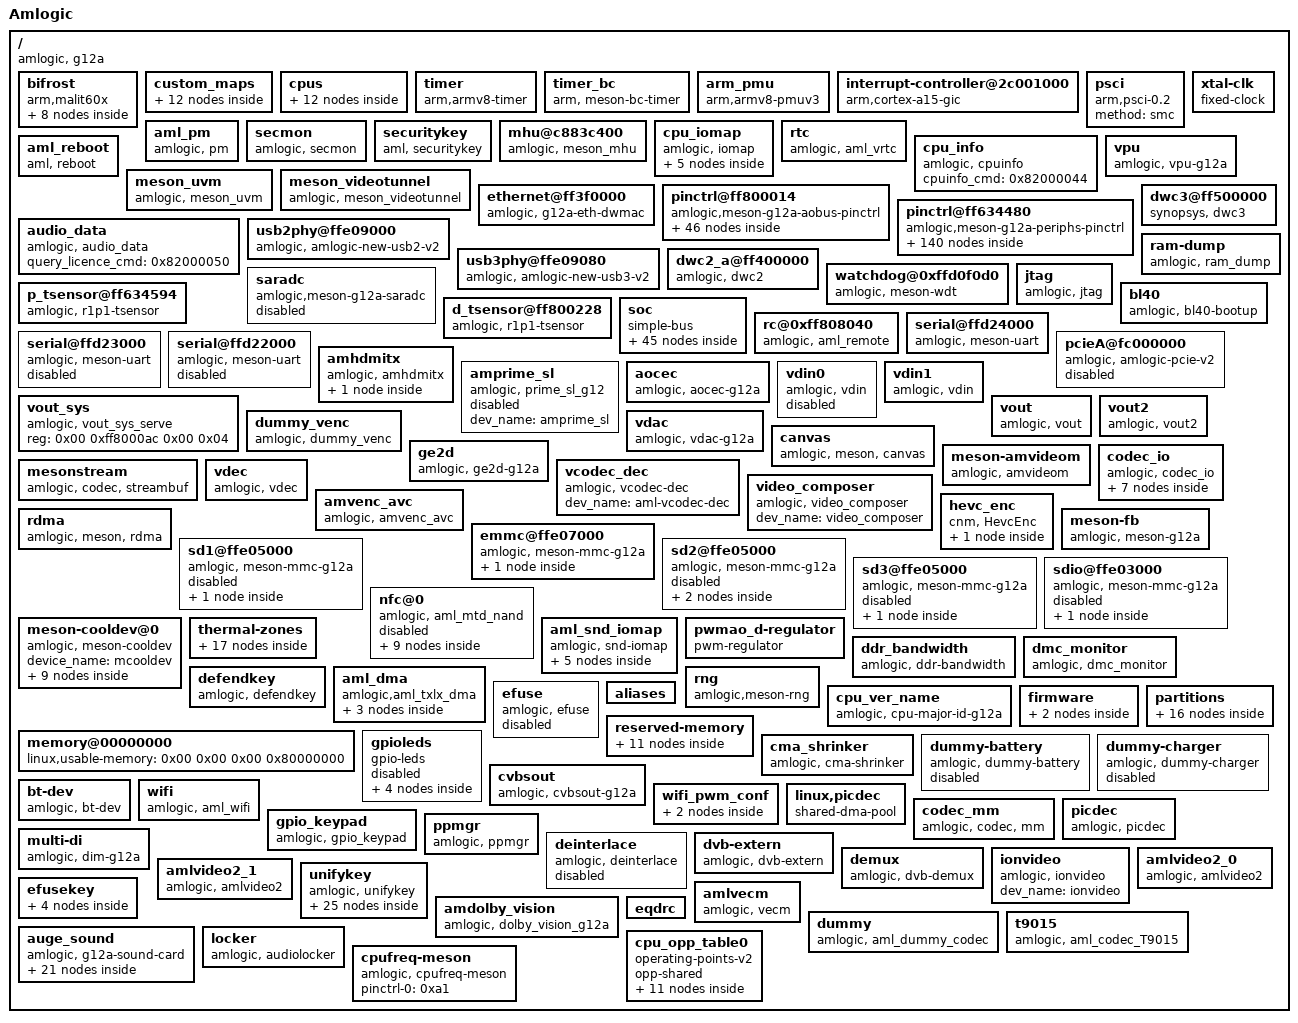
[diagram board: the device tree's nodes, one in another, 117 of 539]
/dts-v1/;

/ {
	model = "Amlogic";
	amlogic-dt-id = "g12a_u212_mtk";
	compatible = "amlogic, g12a";
	interrupt-parent = <0x01>;
	#address-cells = <0x02>;
	#size-cells = <0x02>;

	bifrost {
		compatible = "arm,malit60x", "arm,malit6xx", "arm,mali-midgard";
		#cooling-cells = <0x02>;
		reg = <0x00 0xffe40000 0x00 0x4000 0x00 0xffd01000 0x00 0x1000 0x00 0xff800000 0x00 0x1000 0x00 0xff63c000 0x00 0x1000 0x00 0xffd01000 0x00 0x1000>;
		interrupt-parent = <0x01>;
		interrupts = <0x00 0xa0 0x04 0x00 0xa1 0x04 0x00 0xa2 0x04>;
		interrupt-names = "GPU", "MMU", "JOB";
		num_of_pp = <0x02>;
		sc_mpp = <0x01>;
		clocks = <0x02 0x83 0x02 0x07>;
		clock-names = "gpu_mux", "gp0_pll";
		tbl = <0x03 0x04 0x05 0x06 0x07 0x07>;
		phandle = <0xa2>;

		clk125_cfg {
			clk_freq = <0x7735940>;
			clk_parent = "fclk_div4";
			clkp_freq = <0x1dcd6500>;
			clk_reg = <0xa03>;
			voltage = <0x47e>;
			keep_count = <0x05>;
			threshold = <0x1e 0x78>;
			phandle = <0xa3>;
		};

		dvfs250_cfg {
			clk_freq = <0xee6b280>;
			clk_parent = "fclk_div4";
			clkp_freq = <0x1dcd6500>;
			clk_reg = <0xa01>;
			voltage = <0x47e>;
			keep_count = <0x05>;
			threshold = <0x50 0xaa>;
			phandle = <0xa4>;
		};

		dvfs285_cfg {
			clk_freq = <0x1107a76d>;
			clk_parent = "fclk_div7";
			clkp_freq = <0x1107a76d>;
			clk_reg = <0xe00>;
			voltage = <0x47e>;
			keep_count = <0x05>;
			threshold = <0x00 0x4c>;
			phandle = <0x03>;
		};

		dvfs400_cfg {
			clk_freq = <0x17d78400>;
			clk_parent = "fclk_div5";
			clkp_freq = <0x17d78400>;
			clk_reg = <0xc00>;
			voltage = <0x47e>;
			keep_count = <0x05>;
			threshold = <0x98 0xcf>;
			phandle = <0x04>;
		};

		dvfs500_cfg {
			clk_freq = <0x1dcd6500>;
			clk_parent = "fclk_div4";
			clkp_freq = <0x1dcd6500>;
			clk_reg = <0xa00>;
			voltage = <0x47e>;
			keep_count = <0x05>;
			threshold = <0x26 0xc2>;
			phandle = <0x05>;
		};

		dvfs666_cfg {
			clk_freq = <0x27bc86aa>;
			clk_parent = "fclk_div3";
			clkp_freq = <0x27bc86aa>;
			clk_reg = <0x800>;
			voltage = <0x47e>;
			keep_count = <0x05>;
			threshold = <0x96 0xcb>;
			phandle = <0x06>;
		};

		dvfs800_cfg {
			clk_freq = <0x2faf0800>;
			clk_parent = "fclk_div2p5";
			clkp_freq = <0x2faf0800>;
			clk_reg = <0x600>;
			voltage = <0x47e>;
			keep_count = <0x05>;
			threshold = <0xe6 0xff>;
			phandle = <0xa5>;
		};

		dvfs850_cfg {
			clk_freq = <0x326cef80>;
			clk_parent = "gp0_pll";
			clkp_freq = <0x326cef80>;
			clk_reg = <0x200>;
			voltage = <0x47e>;
			keep_count = <0x05>;
			threshold = <0x9c 0xff>;
			phandle = <0x07>;
		};
	};

	custom_maps {
		mapnum = <0x0c>;
		map0 = <0x08>;
		map1 = <0x09>;
		map2 = <0x0a>;
		map3 = <0x0b>;
		map4 = <0x0c>;
		map5 = <0x0d>;
		map6 = <0x0e>;
		map7 = <0x0f>;
		map8 = <0x10>;
		map9 = <0x11>;
		map10 = <0x12>;
		map11 = <0x13>;
		phandle = <0x35>;

		map_0 {
			mapname = "amlogic-remote-1";
			customcode = <0xfb04>;
			release_delay = <0x50>;
			size = <0x00>;
			keymap;
			phandle = <0x08>;
		};

		map_1 {
			mapname = "amlogic-remote-2";
			customcode = <0xfe01>;
			release_delay = <0x50>;
			size = <0x00>;
			keymap;
			phandle = <0x09>;
		};

		map_2 {
			mapname = "amlogic-remote-3";
			customcode = <0x00>;
			release_delay = <0x50>;
			size = <0x00>;
			keymap;
			phandle = <0x0a>;
		};

		map_3 {
			mapname = "amlogic-remote-4";
			customcode = <0xff00>;
			release_delay = <0x50>;
			size = <0x28>;
			keymap = <0x0b 0x10002 0x20003 0x30004 0x40005 0x50006 0x60007 0x70008 0x80009 0x9000a 0x1e0166 0xa000f 0x450080 0x470067 0x4b006c 0x490061 0x480069 0x4a006a 0x150193 0xb0192 0xc0073 0x180072 0xd0068 0x13006d 0x460078 0x430079 0x5600ac 0x440077 0x400074 0x120071 0x4e0180 0x4f017a 0x50017d 0x51016e 0x4c009e 0x16000e 0x1c00ab 0x1d009c 0x110194 0x4d008b>;
			phandle = <0x0b>;
		};

		map_4 {
			mapname = "amlogic-remote-5";
			customcode = <0x4db2>;
			release_delay = <0x50>;
			size = <0x31>;
			keymap = <0xca0067 0xd2006c 0x990069 0xc1006a 0xce0061 0x800073 0x810072 0xc5009e 0x8200ac 0x9c0071 0xdc0074 0x88008b 0x950077 0x920002 0x930003 0xcc0004 0x8e0005 0x8f0006 0xc80007 0x8a0008 0x8b0009 0xc4000a 0x87000b 0xde0034 0xf3016a 0xc30166 0x8d009c 0xdf000e 0xfe00da 0xe90244 0x910195 0x310188 0x320090 0xcd0189 0x8301ba 0xe6003b 0xe7003c 0xe8003d 0xea00b1 0x4300a8 0x4600d0 0x3400a7 0xe30031 0xe40058 0x330057 0xec0181 0x850192 0x860193 0xeb00b2>;
			phandle = <0x0c>;
		};

		map_5 {
			mapname = "amlogic-remote-6";
			customcode = <0xb24d>;
			release_delay = <0x50>;
			size = <0x2e>;
			keymap = <0xca0067 0xd2006c 0x990069 0xc1006a 0xce001c 0x800073 0x810072 0x8d008d 0xc5009e 0x8200ac 0x9c0071 0xdc0074 0x88008b 0x950077 0x920002 0x930003 0xcc0004 0x8e0005 0x8f0006 0xc80007 0x8a0008 0x8b0009 0xc4000a 0x87000b 0xde0034 0xc30166 0xf3016a 0xdf000e 0xe90244 0x910195 0x310188 0x320090 0xcd0189 0x8301ba 0xe6003b 0xe7003c 0xe8003d 0xea003e 0x4300a8 0x4600d0 0x3400a7 0xe30245 0xe40058 0x330057 0x850192 0x860193>;
			phandle = <0x0d>;
		};

		map_6 {
			mapname = "amlogic-remote-7";
			customcode = <0x04>;
			release_delay = <0x5a>;
			size = <0x2a>;
			keymap = <0xc0074 0x61009c 0x3c0040 0x6b003c 0x6c003d 0x6d003e 0x6e003f 0x5100a5 0x3600a6 0x5000a3 0x3200a8 0x3500a4 0x3400d0 0x1200ac 0x3700a7 0x41016a 0x100067 0x150069 0x24001c 0x16006a 0x11006c 0x1f009e 0x4a0166 0x1d0041 0x140073 0x2700d9 0xe0192 0x170072 0xd0071 0xa0193 0x10002 0x20003 0x30004 0x40005 0x50006 0x60007 0x70008 0x80009 0x9000a 0x25000e 0x0b 0x260042>;
			phandle = <0x0e>;
		};

		map_7 {
			mapname = "amlogic-remote-8";
			customcode = <0xbf00>;
			release_delay = <0x50>;
			size = <0x18>;
			keymap = <0x150067 0x16006c 0x170069 0x18006a 0x140061 0x520073 0x530072 0x51009e 0x700ac 0x460071 0x430074 0xb0002 0xc0003 0xd0004 0xe0005 0xf0006 0x10007 0x110008 0x120009 0x13000a 0xa000b 0x4b0192 0x4c0193 0x600da>;
			phandle = <0x0f>;
		};

		map_8 {
			mapname = "amlogic-remote-9";
			customcode = <0x5e87>;
			release_delay = <0x50>;
			size = <0x2b>;
			keymap = <0x3400a8 0x3600a4 0x35009f 0x38018b 0x320080 0x3300a7 0x390066 0x200188 0x2800db 0x23008b 0x48016a 0xa00ae 0x130166 0xf008a 0xb0067 0x1b0069 0x1c006a 0xc006c 0x15001c 0xd0073 0xe0072 0x1d016c 0x2901a9 0x100192 0x1a0193 0x11019c 0x10002 0x20003 0x30004 0x40005 0x50006 0x60007 0x70008 0x80009 0x9000a 0x0b 0x540172 0x210177 0x180190 0x190191 0x16018e 0x17018f 0x120074>;
			phandle = <0x10>;
		};

		map_9 {
			mapname = "amlogic-remote-10";
			customcode = <0xfd01>;
			release_delay = <0x50>;
			size = <0x27>;
			keymap = <0x8c00a8 0xdd009f 0x98018b 0x91009b 0xc60190 0x9d0188 0x88018f 0x95008b 0xda0191 0xc500ae 0xd6008a 0x830166 0xca0067 0x990069 0xc1006a 0xd2006c 0xce001c 0x850073 0x860072 0x8d016c 0xc7018e 0x800192 0x810193 0x82019c 0x9c0071 0x920002 0x930003 0xcc0004 0x8e0005 0x8f0006 0xc80007 0x8a0008 0x8b0009 0xc4000a 0x87000b 0x840172 0xc90172 0xcd0177 0xdc0074>;
			phandle = <0x11>;
		};

		map_10 {
			mapname = "amlogic-remote-11";
			customcode = <0xbd02>;
			release_delay = <0x50>;
			size = <0x34>;
			keymap = <0x4600a8 0x9500a4 0x47009f 0x48018b 0x490080 0x5000a7 0x51009b 0xa000d9 0x5b0177 0xab0043 0x520066 0x530188 0x5400db 0xd6008d 0x55016a 0xd000ae 0x56008a 0x570166 0xca0067 0x990069 0xc1006a 0xd2006c 0xce001c 0xdd0073 0x8c0072 0x58016c 0x5901a9 0x600192 0x610193 0x62019c 0x890071 0x640002 0x650003 0x660004 0x670005 0x680006 0x690007 0x700008 0x710009 0x72000a 0x63000b 0xa1003b 0xa2003c 0xa3003d 0xa4003e 0x730172 0x740177 0x9a0190 0xcd0191 0x9c018e 0x9d018f 0x450074>;
			phandle = <0x12>;
		};

		map_11 {
			mapname = "amlogic-remote-12";
			customcode = <0xf708>;
			release_delay = <0x50>;
			size = <0x2a>;
			keymap = <0xa0074 0x5018e 0x9018f 0x420190 0x430191 0x4400a8 0x4500d0 0x620041 0x5b003c 0x400166 0x700a4 0xb0080 0x6003d 0x8003e 0x1c009e 0xc00ac 0x660244 0x7e0044 0x67 0x1006c 0x30069 0x2006a 0x1f0061 0x580073 0x5d0072 0x5a0192 0x5f0193 0x7400da 0xd0071 0x110002 0x120003 0x130004 0x140005 0x150006 0x160007 0x170008 0x180009 0x19000a 0x10000b 0x7700d7 0x61009c 0x30000e>;
			phandle = <0x13>;
		};
	};

	cpus {
		#address-cells = <0x02>;
		#size-cells = <0x00>;
		phandle = <0xa6>;

		cpu-map {

			cluster0 {
				phandle = <0xa7>;

				core0 {
					cpu = <0x14>;
				};

				core1 {
					cpu = <0x15>;
				};

				core2 {
					cpu = <0x16>;
				};

				core3 {
					cpu = <0x17>;
				};
			};
		};

		cpu@0 {
			device_type = "cpu";
			compatible = "arm,cortex-a53", "arm,armv8";
			reg = <0x00 0x00>;
			enable-method = "psci";
			cpu-idle-states = <0x18>;
			clocks = <0x02 0x17 0x02 0x16 0x02 0x00>;
			clock-names = "core_clk", "low_freq_clk_parent", "high_freq_clk_parent";
			operating-points-v2 = <0x19>;
			cpu-supply = <0x1a>;
			voltage-tolerance = <0x00>;
			clock-latency = <0xc350>;
			phandle = <0x14>;
		};

		cpu@1 {
			device_type = "cpu";
			compatible = "arm,cortex-a53", "arm,armv8";
			reg = <0x00 0x01>;
			enable-method = "psci";
			cpu-idle-states = <0x18>;
			clocks = <0x02 0x17 0x02 0x16 0x02 0x00>;
			clock-names = "core_clk", "low_freq_clk_parent", "high_freq_clk_parent";
			operating-points-v2 = <0x19>;
			cpu-supply = <0x1a>;
			voltage-tolerance = <0x00>;
			clock-latency = <0xc350>;
			phandle = <0x15>;
		};

		cpu@2 {
			device_type = "cpu";
			compatible = "arm,cortex-a53", "arm,armv8";
			reg = <0x00 0x02>;
			enable-method = "psci";
			cpu-idle-states = <0x18>;
			clocks = <0x02 0x17 0x02 0x16 0x02 0x00>;
			clock-names = "core_clk", "low_freq_clk_parent", "high_freq_clk_parent";
			operating-points-v2 = <0x19>;
			cpu-supply = <0x1a>;
			voltage-tolerance = <0x00>;
			clock-latency = <0xc350>;
			phandle = <0x16>;
		};

		cpu@3 {
			device_type = "cpu";
			compatible = "arm,cortex-a53", "arm,armv8";
			reg = <0x00 0x03>;
			enable-method = "psci";
			cpu-idle-states = <0x18>;
			clocks = <0x02 0x17 0x02 0x16 0x02 0x00>;
			clock-names = "core_clk", "low_freq_clk_parent", "high_freq_clk_parent";
			operating-points-v2 = <0x19>;
			cpu-supply = <0x1a>;
			voltage-tolerance = <0x00>;
			clock-latency = <0xc350>;
			phandle = <0x17>;
		};

		idle-states {
			entry-method = "arm,psci-0.2";

			cpu-sleep-0 {
				compatible = "arm,idle-state";
				arm,psci-suspend-param = <0x10000>;
				local-timer-stop;
				entry-latency-us = <0x1388>;
				exit-latency-us = <0x1388>;
				min-residency-us = <0x3a98>;
				phandle = <0x18>;
			};
		};
	};

	timer {
		compatible = "arm,armv8-timer";
		interrupts = <0x01 0x0d 0xff08 0x01 0x0e 0xff08 0x01 0x0b 0xff08 0x01 0x0a 0xff08>;
	};

	timer_bc {
		compatible = "arm, meson-bc-timer";
		reg = <0x00 0xffd0f190 0x00 0x04 0x00 0xffd0f194 0x00 0x04>;
		timer_name = "Meson TimerF";
		clockevent-rating = <0x12c>;
		clockevent-shift = <0x14>;
		clockevent-features = <0x23>;
		interrupts = <0x00 0x3c 0x01>;
		bit_enable = <0x10>;
		bit_mode = <0x0c>;
		bit_resolution = <0x00>;
	};

	arm_pmu {
		compatible = "arm,armv8-pmuv3";
		interrupts = <0x00 0x89 0x04>;
		reg = <0x00 0xff634680 0x00 0x04>;
		cpumasks = <0x0f>;
		relax-timer-ns = <0x989680>;
		max-wait-cnt = <0x2710>;
	};

	interrupt-controller@2c001000 {
		compatible = "arm,cortex-a15-gic", "arm,cortex-a9-gic";
		#interrupt-cells = <0x03>;
		#address-cells = <0x00>;
		interrupt-controller;
		reg = <0x00 0xffc01000 0x00 0x1000 0x00 0xffc02000 0x00 0x100>;
		interrupts = <0x01 0x09 0xf04>;
		phandle = <0x01>;
	};

	psci {
		compatible = "arm,psci-0.2";
		method = "smc";
	};

	aml_pm {
		compatible = "amlogic, pm";
		status = "okay";
		device_name = "aml_pm";
		debug_reg = <0xff8000a8>;
		exit_reg = <0xff80023c>;
	};

	secmon {
		compatible = "amlogic, secmon";
		memory-region = <0x1b>;
		in_base_func = <0x82000020>;
		out_base_func = <0x82000021>;
		reserve_mem_size = <0x300000>;
	};

	securitykey {
		compatible = "aml, securitykey";
		storage_query = <0x82000060>;
		storage_read = <0x82000061>;
		storage_write = <0x82000062>;
		storage_tell = <0x82000063>;
		storage_verify = <0x82000064>;
		storage_status = <0x82000065>;
		storage_list = <0x82000067>;
		storage_remove = <0x82000068>;
		storage_in_func = <0x82000023>;
		storage_out_func = <0x82000024>;
		storage_block_func = <0x82000025>;
		storage_size_func = <0x82000027>;
		storage_set_enctype = <0x8200006a>;
		storage_get_enctype = <0x8200006b>;
		storage_version = <0x8200006c>;
	};

	mhu@c883c400 {
		compatible = "amlogic, meson_mhu";
		reg = <0x00 0xff63c400 0x00 0x4c 0x00 0xfffe7000 0x00 0x800>;
		interrupts = <0x00 0xd1 0x01 0x00 0xd2 0x01 0x00 0xd5 0x01>;
		#mbox-cells = <0x01>;
		mbox-names = "cpu_to_scp_low", "bl4_to_cpu", "cpu_to_bl4";
		mboxes = <0x1c 0x00 0x1c 0x01 0x1c 0x02>;
		num-chans-to-scp = <0x01>;
		send-isr-bits = <0x05>;
		ack-isr-bits = <0x04>;
		m4-isr-bits = <0x06>;
		mbox-chans = <0x03>;
		phandle = <0x1c>;
	};

	cpu_iomap {
		compatible = "amlogic, iomap";
		#address-cells = <0x02>;
		#size-cells = <0x02>;
		ranges;

		io_cbus_base {
			reg = <0x00 0xffd00000 0x00 0x26000>;
		};

		io_apb_base {
			reg = <0x00 0xffe01000 0x00 0x7f000>;
		};

		io_aobus_base {
			reg = <0x00 0xff800000 0x00 0xb000>;
		};

		io_vapb_base {
			reg = <0x00 0xff900000 0x00 0x50000>;
		};

		io_hiu_base {
			reg = <0x00 0xff63c000 0x00 0x2000>;
		};
	};

	xtal-clk {
		compatible = "fixed-clock";
		clock-frequency = <0x16e3600>;
		clock-output-names = "xtal";
		#clock-cells = <0x00>;
		phandle = <0x1f>;
	};

	rtc {
		compatible = "amlogic, aml_vrtc";
		alarm_reg_addr = <0xff8000a8>;
		timer_e_addr = <0xffd0f188>;
		init_date = "2015/01/01";
		status = "okay";
	};

	cpu_info {
		compatible = "amlogic, cpuinfo";
		status = "okay";
		cpuinfo_cmd = <0x82000044>;
	};

	aml_reboot {
		compatible = "aml, reboot";
		sys_reset = <0x84000009>;
		sys_poweroff = <0x84000008>;
	};

	vpu {
		compatible = "amlogic, vpu-g12a";
		dev_name = "vpu";
		status = "okay";
		clocks = <0x02 0x95 0x02 0x4c 0x02 0x87 0x02 0x8b 0x02 0x8c>;
		clock-names = "vapb_clk", "vpu_intr_gate", "vpu_clk0", "vpu_clk1", "vpu_clk";
		clk_level = <0x07>;
	};

	meson_uvm {
		compatible = "amlogic, meson_uvm";
		status = "okay";
	};

	meson_videotunnel {
		compatible = "amlogic, meson_videotunnel";
		status = "okay";
	};

	ethernet@ff3f0000 {
		compatible = "amlogic, g12a-eth-dwmac", "snps,dwmac";
		reg = <0x00 0xff3f0000 0x00 0x10000 0x00 0xff634540 0x00 0x08 0x00 0xff64c000 0x00 0xa0 0x00 0xffd01008 0x00 0x04>;
		reg-names = "eth_base", "eth_cfg", "eth_pll", "eth_reset";
		interrupts = <0x00 0x08 0x01>;
		interrupt-names = "macirq";
		status = "okay";
		clocks = <0x02 0x38>;
		clock-names = "ethclk81";
		pll_val = <0x9c0040a 0x927e0000 0xac5f49e5>;
		analog_val = <0x20200000 0xc000 0x23>;
		pinctrl-names = "internal_eth_pins", "internal_gpio_pins";
		mc_val = <0x4be04>;
		internal_phy = <0x01>;
		phandle = <0xa8>;
	};

	pinctrl@ff800014 {
		compatible = "amlogic,meson-g12a-aobus-pinctrl";
		#address-cells = <0x02>;
		#size-cells = <0x02>;
		ranges;
		phandle = <0xa9>;

		ao-bank@ff800014 {
			reg = <0x00 0xff800014 0x00 0x08 0x00 0xff800024 0x00 0x14 0x00 0xff80001c 0x00 0x08>;
			reg-names = "mux", "gpio", "drive-strength";
			gpio-controller;
			#gpio-cells = <0x02>;
			phandle = <0x71>;
		};

		sd_to_ao_uart_clr_pins {
			phandle = <0x48>;

			mux {
				groups = "GPIOAO_0", "GPIOAO_1";
				function = "gpio_aobus";
			};
		};

		sd_to_ao_uart_pins {
			phandle = <0x4a>;

			mux {
				groups = "uart_ao_tx_a", "uart_ao_rx_a";
				function = "uart_ao_a";
				bias-pull-up;
				input-enable;
			};
		};

		ao_uart {
			phandle = <0xaa>;

			mux {
				groups = "uart_ao_tx_a", "uart_ao_rx_a";
				function = "uart_ao_a";
			};
		};

		ao_b_uart {
			phandle = <0x27>;

			mux {
				groups = "uart_ao_tx_b_2", "uart_ao_rx_b_3";
				function = "uart_ao_b";
			};
		};

		ao_i2c_pins1 {
			phandle = <0xab>;

			mux {
				groups = "i2c_ao_sck", "i2c_ao_sda";
				function = "i2c_ao";
				drive-strength = <0x02>;
			};
		};

		ao_i2c_pins2 {
			phandle = <0xac>;

			mux {
				groups = "i2c_ao_sck_e", "i2c_ao_sda_e";
				function = "i2c_ao";
				drive-strength = <0x02>;
			};
		};

		ao_i2c_slave_pins {
			phandle = <0x26>;

			mux {
				groups = "i2c_ao_slave_sck", "i2c_ao_slave_sda";
				function = "i2c_ao_slave";
			};
		};

		pwm_ao_a {
			phandle = <0xad>;

			mux {
				groups = "pwm_ao_a";
				function = "pwm_ao_a";
			};
		};

		pwm_ao_a_hiz {
			phandle = <0xae>;

			mux {
				groups = "pwm_ao_a_hiz";
				function = "pwm_ao_a";
			};
		};

		pwm_ao_b {
			phandle = <0xaf>;

			mux {
				groups = "pwm_ao_b";
				function = "pwm_ao_b";
			};
		};

		pwm_ao_c_pins1 {
			phandle = <0xb0>;

			mux {
				groups = "pwm_ao_c_4";
				function = "pwm_ao_c";
			};
		};

		pwm_ao_c_pins2 {
			phandle = <0xb1>;

			mux {
				groups = "pwm_ao_c_6";
				function = "pwm_ao_c";
			};
		};

		pwm_ao_c_hiz {
			phandle = <0xb2>;

			mux {
				groups = "pwm_ao_c_hiz_4";
				function = "pwm_ao_c";
			};
		};

		pwm_ao_d_pins1 {
			phandle = <0xb3>;

			mux {
				groups = "pwm_ao_d_5";
				function = "pwm_ao_d";
			};
		};

		pwm_ao_d_pins2 {
			phandle = <0xb4>;

			mux {
				groups = "pwm_ao_d_10";
				function = "pwm_ao_d";
			};
		};

		pwm_ao_d_pins3 {
			phandle = <0xa1>;

			mux {
				groups = "pwm_ao_d_e";
				function = "pwm_ao_d";
			};
		};

		ao_ceca {
			phandle = <0xb5>;

			mux {
				groups = "cec_ao_a";
				function = "cec_ao";
			};
		};

		ao_cecb {
			phandle = <0xb6>;

			mux {
				groups = "cec_ao_b";
				function = "cec_ao";
			};
		};

		jtag_apao_pin {
			phandle = <0x20>;

			mux {
				groups = "jtag_a_tdi", "jtag_a_tdo", "jtag_a_clk", "jtag_a_tms";
				function = "jtag_a";
			};
		};

		remote_pin {
			phandle = <0x34>;

			mux {
				groups = "remote_input_ao";
				function = "remote_input_ao";
			};
		};

		irblaster_pin {
			phandle = <0x28>;

			mux {
				groups = "remote_out_ao";
				function = "remote_out_ao";
			};
		};

		dvb_s_ts0_pins {
			phandle = <0xb7>;

			tsin_a_ao {
				groups = "tsin_a_sop_ao", "tsin_a_valid_ao", "tsin_a_clk_ao", "tsin_a_din0_ao";
				function = "tsin_a_ao";
			};

			tsin_a {
				groups = "tsin_a_sop_ao", "tsin_a_valid_ao", "tsin_a_clk_ao", "tsin_a_din0_ao";
				function = "tsin_a_ao";
			};
		};
	};

	pinctrl@ff634480 {
		compatible = "amlogic,meson-g12a-periphs-pinctrl";
		#address-cells = <0x02>;
		#size-cells = <0x02>;
		ranges;
		phandle = <0xb8>;

		banks@ff6346c0 {
			reg = <0x00 0xff6346c0 0x00 0x40 0x00 0xff6344e8 0x00 0x18 0x00 0xff634520 0x00 0x18 0x00 0xff634440 0x00 0x4c 0x00 0xff634740 0x00 0x1c>;
			reg-names = "mux", "pull", "pull-enable", "gpio", "drive-strength";
			gpio-controller;
			#gpio-cells = <0x02>;
			phandle = <0x23>;
		};

		emmc_clk_cmd_pins {
			phandle = <0x42>;

			mux {
				groups = "emmc_clk", "emmc_cmd";
				function = "emmc";
				input-enable;
				bias-pull-up;
			};
		};

		emmc_conf_pull_up {
			phandle = <0x43>;

			mux {
				groups = "emmc_nand_d7", "emmc_nand_d6", "emmc_nand_d5", "emmc_nand_d4", "emmc_nand_d3", "emmc_nand_d2", "emmc_nand_d1", "emmc_nand_d0", "emmc_clk", "emmc_cmd";
				function = "emmc";
				input-enable;
				bias-pull-up;
			};
		};

		emmc_conf_pull_done {
			phandle = <0x44>;

			mux {
				groups = "emmc_nand_ds";
				function = "emmc";
				input-enable;
				bias-pull-down;
			};
		};

		sd_clk_cmd_pins {
			phandle = <0x46>;

			mux {
				groups = "sdcard_cmd_c";
				function = "sdcard";
				input-enable;
				bias-pull-up;
				drive-strength = <0x03>;
			};

			mux1 {
				groups = "sdcard_clk_c";
				function = "sdcard";
				bias-pull-up;
				output-high;
				drive-strength = <0x03>;
			};
		};

		sd_all_pins {
			phandle = <0x45>;

			mux {
				groups = "sdcard_d0_c", "sdcard_d1_c", "sdcard_d2_c", "sdcard_d3_c", "sdcard_cmd_c";
				function = "sdcard";
				input-enable;
				bias-pull-up;
				drive-strength = <0x03>;
			};

			mux1 {
				groups = "sdcard_clk_c";
				function = "sdcard";
				bias-pull-up;
				output-high;
				drive-strength = <0x03>;
			};
		};

		sd_1bit_pins {
			phandle = <0x47>;

			mux {
				groups = "sdcard_d0_c", "sdcard_cmd_c";
				function = "sdcard";
				input-enable;
				bias-pull-up;
				drive-strength = <0x03>;
			};

			mux1 {
				groups = "sdcard_clk_c";
				function = "sdcard";
				bias-pull-up;
				output-high;
				drive-strength = <0x03>;
			};
		};

		sd_clr_all_pins {
			phandle = <0x4e>;

			mux {
				groups = "GPIOC_0", "GPIOC_1", "GPIOC_2", "GPIOC_3", "GPIOC_5";
				function = "gpio_periphs";
				output-high;
			};

			mux1 {
				groups = "GPIOC_4";
				function = "gpio_periphs";
				output-low;
			};
		};

		sd_clr_noall_pins {
			phandle = <0x4d>;

			mux {
				groups = "GPIOC_0", "GPIOC_1", "GPIOC_4", "GPIOC_5";
				function = "gpio_periphs";
				output-high;
			};
		};

		ao_to_sd_uart_pins {
			phandle = <0x49>;

			mux {
				groups = "uart_ao_tx_a_c3", "uart_ao_rx_a_c2";
				function = "uart_ao_a_ee";
				bias-pull-up;
				input-enable;
			};
		};

		sdio_clk_cmd_pins {
			phandle = <0x52>;

			mux {
				groups = "sdio_clk", "sdio_cmd";
				function = "sdio";
				input-enable;
				bias-pull-up;
				drive-strength = <0x03>;
			};
		};

		sdio_all_pins {
			phandle = <0x51>;

			mux {
				groups = "sdio_d0", "sdio_d1", "sdio_d2", "sdio_d3", "sdio_clk", "sdio_cmd";
				function = "sdio";
				input-enable;
				bias-pull-up;
				drive-strength = <0x03>;
			};
		};

		sdio_x_clk_cmd_pins {
			phandle = <0x50>;

			mux {
				groups = "GPIOX_5";
				function = "gpio_periphs";
				input-enable;
				bias-pull-up;
				drive-strength = <0x03>;
			};

			mux1 {
				groups = "GPIOX_4";
				function = "gpio_periphs";
				bias-pull-up;
				output-high;
				drive-strength = <0x03>;
			};
		};

		sdio_x_all_pins {
			phandle = <0x4f>;

			mux {
				groups = "GPIOX_0", "GPIOX_1", "GPIOX_2", "GPIOX_3", "GPIOX_5";
				function = "gpio_periphs";
				input-enable;
				bias-pull-up;
				drive-strength = <0x03>;
			};

			mux1 {
				groups = "GPIOX_4";
				function = "gpio_periphs";
				bias-pull-up;
				output-high;
				drive-strength = <0x03>;
			};
		};

		sdio_x_en_pins {
			phandle = <0x4c>;

			mux {
				groups = "sdio_dummy";
				function = "sdio";
				bias-pull-up;
				output-high;
			};
		};

		sdio_x_clr_pins {
			phandle = <0x4b>;

			mux {
				groups = "GPIOV_0";
				function = "gpio_periphs";
				bias-pull-up;
				output-low;
			};

			mux1 {
				groups = "GPIOX_4";
				function = "gpio_periphs";
				output-low;
			};
		};

		all_nand_pins {
			phandle = <0x53>;

			mux {
				groups = "emmc_nand_d0", "emmc_nand_d1", "emmc_nand_d2", "emmc_nand_d3", "emmc_nand_d4", "emmc_nand_d5", "emmc_nand_d6", "emmc_nand_d7", "nand_ce0", "nand_ale", "nand_cle", "nand_wen_clk", "nand_ren_wr", "nand_rb0";
				function = "nand";
				input-enable;
			};
		};

		nand_cs {
			phandle = <0x54>;

			mux {
				groups = "nand_ce0";
				function = "nand";
			};
		};

		i2c0_pins1 {
			phandle = <0xb9>;

			mux {
				groups = "i2c0_sda_c", "i2c0_sck_c";
				function = "i2c0";
				drive-strength = <0x02>;
			};
		};

		i2c0_pins2 {
			phandle = <0x22>;

			mux {
				groups = "i2c0_sda_z0", "i2c0_sck_z1";
				function = "i2c0";
				drive-strength = <0x02>;
			};
		};

		i2c0_pins3 {
			phandle = <0xba>;

			mux {
				groups = "i2c0_sda_z7", "i2c0_sck_z8";
				function = "i2c0";
				drive-strength = <0x02>;
			};
		};

		i2c1_pins1 {
			phandle = <0xbb>;

			mux {
				groups = "i2c1_sda_x", "i2c1_sck_x";
				function = "i2c1";
				drive-strength = <0x02>;
			};
		};

		i2c1_pins2 {
			phandle = <0xbc>;

			mux {
				groups = "i2c1_sda_h2", "i2c1_sck_h3";
				function = "i2c1";
				drive-strength = <0x02>;
			};
		};

		i2c1_pins3 {
			phandle = <0xbd>;

			mux {
				groups = "i2c1_sda_h6", "i2c1_sck_h7";
				function = "i2c1";
				drive-strength = <0x02>;
			};
		};

		i2c2_pins1 {
			phandle = <0xbe>;

			mux {
				groups = "i2c2_sda_x", "i2c2_sck_x";
				function = "i2c2";
				drive-strength = <0x02>;
			};
		};

		i2c2_pins2 {
			phandle = <0x24>;

			mux {
				groups = "i2c2_sda_z", "i2c2_sck_z";
				function = "i2c2";
				drive-strength = <0x02>;
			};
		};

		i2c3_pins1 {
			phandle = <0x3d>;

			mux {
				groups = "i2c3_sda_h", "i2c3_sck_h";
				function = "i2c3";
				drive-strength = <0x02>;
			};
		};

		i2c3_pins2 {
			phandle = <0x25>;

			mux {
				groups = "i2c3_sda_a", "i2c3_sck_a";
				function = "i2c3";
				drive-strength = <0x02>;
			};
		};

		pwm_a {
			phandle = <0xbf>;

			mux {
				groups = "pwm_a";
				function = "pwm_a";
			};
		};

		pwm_b_pins1 {
			phandle = <0xc0>;

			mux {
				groups = "pwm_b_x7";
				function = "pwm_b";
			};
		};

		pwm_b_pins2 {
			phandle = <0xc1>;

			mux {
				groups = "pwm_b_x19";
				function = "pwm_b";
			};
		};

		pwm_c_pins1 {
			phandle = <0xc2>;

			mux {
				groups = "pwm_c_c4";
				function = "pwm_c";
			};
		};

		pwm_c_pins2 {
			phandle = <0xc3>;

			mux {
				groups = "pwm_c_x5";
				function = "pwm_c";
			};
		};

		pwm_c_pins3 {
			phandle = <0xc4>;

			mux {
				groups = "pwm_c_x8";
				function = "pwm_c";
			};
		};

		pwm_d_pins1 {
			phandle = <0xc5>;

			mux {
				groups = "pwm_d_x3";
				function = "pwm_d";
			};
		};

		pwm_d_pins2 {
			phandle = <0xc6>;

			mux {
				groups = "pwm_d_x6";
				function = "pwm_d";
			};
		};

		pwm_e {
			phandle = <0xc7>;

			mux {
				groups = "pwm_e";
				function = "pwm_e";
				drive-strength = <0x00>;
			};
		};

		pwm_f_pins1 {
			phandle = <0xc8>;

			mux {
				groups = "pwm_f_x";
				function = "pwm_f";
			};
		};

		pwm_f_pins2 {
			phandle = <0xc9>;

			mux {
				groups = "pwm_f_h";
				function = "pwm_f";
			};
		};

		spicc0_pins_x {
			phandle = <0xca>;

			mux {
				groups = "spi0_mosi_x", "spi0_miso_x", "spi0_clk_x";
				function = "spi0";
				drive-strength = <0x01>;
			};
		};

		spicc0_pins_c {
			phandle = <0xcb>;

			mux {
				groups = "spi0_mosi_c", "spi0_miso_c", "spi0_ss0_c", "spi0_clk_c";
				function = "spi0";
				drive-strength = <0x01>;
			};
		};

		spicc1_pins {
			phandle = <0xcc>;

			mux {
				groups = "spi1_mosi", "spi1_miso", "spi1_clk";
				function = "spi1";
				drive-strength = <0x01>;
			};
		};

		a_uart {
			phandle = <0x36>;

			mux {
				groups = "uart_tx_a", "uart_rx_a", "uart_cts_a", "uart_rts_a";
				function = "uart_a";
			};
		};

		b_uart {
			phandle = <0x37>;

			mux {
				groups = "uart_tx_b", "uart_rx_b";
				function = "uart_b";
			};
		};

		c_uart {
			phandle = <0x38>;

			mux {
				groups = "uart_tx_c", "uart_rx_c";
				function = "uart_c";
			};
		};

		hdmitx_hpd {
			phandle = <0x3a>;

			mux {
				groups = "hdmitx_hpd_in";
				function = "hdmitx";
				bias-disable;
			};
		};

		hdmitx_hpd_gpio {
			phandle = <0x3c>;

			mux {
				groups = "GPIOH_1";
				function = "gpio_periphs";
				bias-disable;
			};
		};

		hdmitx_ddc {
			phandle = <0x3b>;

			mux {
				groups = "hdmitx_sda", "hdmitx_sck";
				function = "hdmitx";
				bias-disable;
				drive-strength = <0x03>;
			};
		};

		ee_ceca {
			phandle = <0x3e>;

			mux {
				groups = "cec_ao_a_ee";
				function = "cec_ao_ee";
			};
		};

		ee_cecb {
			phandle = <0x3f>;

			mux {
				groups = "cec_ao_b_ee";
				function = "cec_ao_ee";
			};
		};

		internal_eth_pins {
			phandle = <0xcd>;

			mux {
				groups = "eth_link_led", "eth_act_led";
				function = "eth";
			};
		};

		internal_gpio_pins {
			phandle = <0xce>;

			mux {
				groups = "GPIOZ_14", "GPIOZ_15";
				function = "gpio_periphs";
				bias-disable;
				input-enable;
			};
		};

		external_eth_pins {
			phandle = <0xcf>;

			mux {
				groups = "eth_mdio", "eth_mdc", "eth_rgmii_rx_clk", "eth_rx_dv", "eth_rxd0", "eth_rxd1", "eth_rxd2_rgmii", "eth_rxd3_rgmii", "eth_rgmii_tx_clk", "eth_txen", "eth_txd0", "eth_txd1", "eth_txd2_rgmii", "eth_txd3_rgmii";
				function = "eth";
				drive-strength = <0x03>;
			};
		};

		jtag_apee_pin {
			phandle = <0x21>;

			mux {
				groups = "jtag_b_tdi", "jtag_b_tdo", "jtag_b_clk", "jtag_b_tms";
				function = "jtag_b";
			};
		};

		tdmout_a {
			phandle = <0x2c>;

			mux {
				groups = "tdma_sclk", "tdma_fs", "tdma_dout0";
				function = "tdma_out";
			};
		};

		tdmin_a {
			phandle = <0x2d>;

			mux {
				groups = "tdma_din1";
				function = "tdma_in";
			};
		};

		tdmb_mclk {
			phandle = <0x2e>;

			mux {
				groups = "mclk0_a";
				function = "mclk0";
				drive-strength = <0x02>;
			};
		};

		tdmout_b {
			phandle = <0x2f>;

			mux {
				groups = "tdmb_sclk", "tdmb_fs", "tdmb_dout0";
				function = "tdmb_out";
				drive-strength = <0x02>;
			};
		};

		tdmin_b {
			phandle = <0x30>;

			mux {
				groups = "tdmb_din1";
				function = "tdmb_in";
				drive-strength = <0x02>;
			};
		};

		tdmc_mclk {
			phandle = <0xd0>;

			mux {
				groups = "mclk1_a";
				function = "mclk1";
			};
		};

		tdmout_c {
			phandle = <0xd1>;

			mux {
				groups = "tdmc_sclk_a", "tdmc_fs_a", "tdmc_dout0_a";
				function = "tdmc_out";
			};
		};

		tdmin_c {
			phandle = <0xd2>;

			mux {
				groups = "tdmc_din1_a";
				function = "tdmc_in";
			};
		};

		spdifin {
			phandle = <0xd3>;

			mux {
				groups = "spdif_in_h";
				function = "spdif_in";
			};
		};

		spdifout {
			phandle = <0x31>;

			mux {
				groups = "spdif_out_h";
				function = "spdif_out";
			};
		};

		spdifout_a_mute {
			phandle = <0x32>;

			mux {
				groups = "GPIOH_4";
				function = "gpio_periphs";
			};
		};

		pdmin {
			phandle = <0x33>;

			mux {
				groups = "pdm_din0_a", "pdm_din2_a", "pdm_dclk_a";
				function = "pdm";
			};
		};

		dvb_s_ts1_pins {
			phandle = <0x79>;

			tsin_b {
				groups = "tsin_b_sop_z", "tsin_b_valid_z", "tsin_b_clk_z", "tsin_b_din0_z";
				function = "tsin_b";
			};
		};
	};

	audio_data {
		compatible = "amlogic, audio_data";
		query_licence_cmd = <0x82000050>;
		status = "okay";
		phandle = <0xd4>;
	};

	dwc3@ff500000 {
		compatible = "synopsys, dwc3";
		status = "okay";
		reg = <0x00 0xff500000 0x00 0x100000>;
		interrupts = <0x00 0x1e 0x04>;
		usb-phy = <0x1d 0x1e>;
		cpu-type = "gxl";
		clock-src = "usb3.0";
		clocks = <0x02 0x41>;
		clock-names = "dwc_general";
		phandle = <0xd5>;
	};

	usb2phy@ffe09000 {
		compatible = "amlogic, amlogic-new-usb2-v2";
		status = "okay";
		reg = <0x00 0xffe09000 0x00 0x80 0x00 0xffd01008 0x00 0x100 0x00 0xff636000 0x00 0x2000 0x00 0xff63a000 0x00 0x2000>;
		pll-setting-1 = <0x9400414>;
		pll-setting-2 = <0x927e0000>;
		pll-setting-3 = <0xac5f49e5>;
		pll-setting-4 = <0xfe18>;
		pll-setting-5 = <0x8000fff>;
		pll-setting-6 = <0x78000>;
		pll-setting-7 = <0xe0004>;
		pll-setting-8 = <0xe000c>;
		portnum = <0x02>;
		phandle = <0x1d>;
	};

	usb3phy@ffe09080 {
		compatible = "amlogic, amlogic-new-usb3-v2";
		status = "okay";
		reg = <0x00 0xffe09080 0x00 0x20>;
		phy-reg = <0xff646000>;
		phy-reg-size = <0x2000>;
		usb2-phy-reg = <0xffe09000>;
		usb2-phy-reg-size = <0x80>;
		interrupts = <0x00 0x10 0x04>;
		clocks = <0x02 0x18>;
		clock-names = "pcie_refpll";
		portnum = <0x01>;
		otg = <0x00>;
		phandle = <0x1e>;
	};

	dwc2_a@ff400000 {
		compatible = "amlogic, dwc2";
		status = "okay";
		device_name = "dwc2_a";
		reg = <0x00 0xff400000 0x00 0x40000>;
		interrupts = <0x00 0x1f 0x04>;
		pl-periph-id = <0x00>;
		clock-src = "usb0";
		port-id = <0x00>;
		port-type = <0x02>;
		port-speed = <0x00>;
		port-config = <0x00>;
		port-dma = <0x00>;
		port-id-mode = <0x00>;
		usb-fifo = <0x2d8>;
		cpu-type = "v2";
		phy-reg = <0xffe09000>;
		phy-reg-size = <0xa0>;
		phy-interface = <0x00>;
		clocks = <0x02 0x41 0x02 0x49>;
		clock-names = "usb_general", "usb1";
		controller-type = <0x01>;
		phandle = <0xd6>;
	};

	watchdog@0xffd0f0d0 {
		compatible = "amlogic, meson-wdt";
		status = "okay";
		default_timeout = <0x0a>;
		reset_watchdog_method = <0x01>;
		reset_watchdog_time = <0x02>;
		shutdown_timeout = <0x0a>;
		firmware_timeout = <0x06>;
		suspend_timeout = <0x06>;
		reg = <0x00 0xffd0f0d0 0x00 0x10>;
		clock-names = "xtal";
		clocks = <0x1f>;
		phandle = <0xd7>;
	};

	ram-dump {
		compatible = "amlogic, ram_dump";
		status = "okay";
		reg = <0x00 0xff6345e0 0x00 0x04>;
		reg-names = "PREG_STICKY_REG8";
		store_device = "data";
	};

	jtag {
		compatible = "amlogic, jtag";
		status = "okay";
		select = "disable";
		pinctrl-names = "jtag_apao_pins", "jtag_apee_pins";
		pinctrl-0 = <0x20>;
		pinctrl-1 = <0x21>;
	};

	saradc {
		compatible = "amlogic,meson-g12a-saradc";
		status = "disabled";
		#io-channel-cells = <0x01>;
		clocks = <0x1f 0x02 0x105>;
		clock-names = "xtal", "saradc_clk";
		interrupts = <0x00 0xc8 0x01>;
		reg = <0x00 0xff809000 0x00 0x48>;
		phandle = <0xd8>;
	};

	p_tsensor@ff634594 {
		compatible = "amlogic, r1p1-tsensor";
		device_name = "meson-pthermal";
		status = "okay";
		reg = <0x00 0xff634800 0x00 0x50 0x00 0xff800268 0x00 0x04>;
		cal_type = <0x01>;
		cal_a = <0x144>;
		cal_b = <0x1a8>;
		cal_c = <0xc57>;
		cal_d = <0x24c3>;
		rtemp = <0x1c138>;
		interrupts = <0x00 0x23 0x00>;
		clocks = <0x02 0xd6>;
		clock-names = "ts_comp";
		#thermal-sensor-cells = <0x01>;
		phandle = <0x58>;
	};

	d_tsensor@ff800228 {
		compatible = "amlogic, r1p1-tsensor";
		device_name = "meson-dthermal";
		status = "okay";
		reg = <0x00 0xff634c00 0x00 0x50 0x00 0xff800230 0x00 0x04>;
		cal_type = <0x01>;
		cal_a = <0x144>;
		cal_b = <0x1a8>;
		cal_c = <0xc57>;
		cal_d = <0x24c3>;
		rtemp = <0x1c138>;
		interrupts = <0x00 0x24 0x00>;
		clocks = <0x02 0xd6>;
		clock-names = "ts_comp";
		#thermal-sensor-cells = <0x01>;
		phandle = <0x5e>;
	};

	bl40 {
		compatible = "amlogic, bl40-bootup";
		status = "okay";
		phandle = <0xd9>;
	};

	soc {
		compatible = "simple-bus";
		#address-cells = <0x02>;
		#size-cells = <0x02>;
		ranges;

		cbus@ffd00000 {
			compatible = "simple-bus";
			reg = <0x00 0xffd00000 0x00 0x26000>;
			#address-cells = <0x02>;
			#size-cells = <0x02>;
			ranges = <0x00 0x00 0x00 0xffd00000 0x00 0x26000>;
			phandle = <0xda>;

			interrupt-controller@f080 {
				compatible = "amlogic,meson-gpio-intc", "amlogic,meson-g12a-gpio-intc";
				reg = <0x00 0xf080 0x00 0x10>;
				interrupt-controller;
				#interrupt-cells = <0x02>;
				amlogic,channel-interrupts = <0x40 0x41 0x42 0x43 0x44 0x45 0x46 0x47>;
				status = "okay";
				phandle = <0xdb>;
			};

			meson_clk_msr {
				compatible = "amlogic, gxl_measure";
				reg = <0x00 0x18004 0x00 0x04 0x00 0x1800c 0x00 0x04>;
				ringctrl = <0xff6345fc>;
			};

			pwm@1b000 {
				compatible = "amlogic,g12a-ee-pwm";
				reg = <0x00 0x1b000 0x00 0x20>;
				#pwm-cells = <0x03>;
				clocks = <0x1f 0x1f 0x1f 0x1f>;
				clock-names = "clkin0", "clkin1", "clkin2", "clkin3";
				status = "disabled";
				phandle = <0xdc>;
			};

			pwm@1a000 {
				compatible = "amlogic,g12a-ee-pwm";
				reg = <0x00 0x1a000 0x00 0x20>;
				#pwm-cells = <0x03>;
				clocks = <0x1f 0x1f 0x1f 0x1f>;
				clock-names = "clkin0", "clkin1", "clkin2", "clkin3";
				status = "disabled";
				phandle = <0xdd>;
			};

			pwm@19000 {
				compatible = "amlogic,g12a-ee-pwm";
				reg = <0x00 0x19000 0x00 0x20>;
				#pwm-cells = <0x03>;
				clocks = <0x1f 0x1f 0x1f 0x1f>;
				clock-names = "clkin0", "clkin1", "clkin2", "clkin3";
				status = "okay";
				phandle = <0x72>;
			};

			i2c@1f000 {
				compatible = "amlogic,meson-g12a-i2c";
				status = "okay";
				reg = <0x00 0x1f000 0x00 0x20>;
				interrupts = <0x00 0x15 0x01 0x00 0x5b 0x01>;
				#address-cells = <0x01>;
				#size-cells = <0x00>;
				clocks = <0x02 0x2a>;
				clock-names = "clk_i2c";
				pinctrl-names = "default";
				pinctrl-0 = <0x22>;
				clock-frequency = <0x61a80>;
				phandle = <0xde>;

				gt9xx@5d {
					compatible = "goodix,gt9xx";
					status = "disabled";
					reg = <0x5d>;
					reset-gpio = <0x23 0x0a 0x00>;
					irq-gpio = <0x23 0x04 0x00>;
				};

				ftxx@38 {
					compatible = "focaltech,fts";
					status = "disabled";
					reg = <0x38>;
					reset-gpio = <0x23 0x0a 0x00>;
					irq-gpio = <0x23 0x04 0x00>;
					x_max = <0x258>;
					y_max = <0x400>;
					max-touch-number = <0x0a>;
				};
			};

			i2c@1e000 {
				compatible = "amlogic,meson-g12a-i2c";
				status = "disabled";
				reg = <0x00 0x1e000 0x00 0x20>;
				interrupts = <0x00 0xd6 0x01 0x00 0x5c 0x01>;
				#address-cells = <0x01>;
				#size-cells = <0x00>;
				clocks = <0x02 0x2a>;
				clock-names = "clk_i2c";
				phandle = <0xdf>;
			};

			i2c@1d000 {
				compatible = "amlogic,meson-g12a-i2c";
				status = "okay";
				reg = <0x00 0x1d000 0x00 0x20>;
				interrupts = <0x00 0xd7 0x01 0x00 0x5e 0x01>;
				#address-cells = <0x01>;
				#size-cells = <0x00>;
				clocks = <0x02 0x2a>;
				clock-names = "clk_i2c";
				pinctrl-names = "default";
				pinctrl-0 = <0x24>;
				clock-frequency = <0x186a0>;
				phandle = <0x78>;
			};

			i2c@1c000 {
				compatible = "amlogic,meson-g12a-i2c";
				status = "disabled";
				reg = <0x00 0x1c000 0x00 0x20>;
				interrupts = <0x00 0x27 0x01 0x00 0x5f 0x01>;
				#address-cells = <0x01>;
				#size-cells = <0x00>;
				clocks = <0x02 0x2a>;
				clock-names = "clk_i2c";
				pinctrl-names = "default";
				pinctrl-0 = <0x25>;
				clock-frequency = <0x493e0>;
				phandle = <0xe0>;

				ad82584f_62@62 {
					compatible = "ESMT, ad82584f";
					#sound-dai-cells = <0x00>;
					reg = <0x31>;
					status = "disabled";
					reset_pin = <0x23 0x37 0x00>;
					phandle = <0xe1>;
				};

				tas5707_36@36 {
					compatible = "ti,tas5707";
					#sound-dai-cells = <0x00>;
					reg = <0x1b>;
					status = "disabled";
					reset_pin = <0x23 0x37 0x00>;
					phandle = <0xe2>;
				};

				bl_extern_i2c {
					compatible = "amlogic, bl_extern_i2c";
					status = "disabled";
					reg = <0x2c>;
					dev_name = "lp8556";
				};
			};

			spi@13000 {
				compatible = "amlogic,meson-g12a-spicc";
				reg = <0x00 0x13000 0x00 0x44>;
				interrupts = <0x00 0x51 0x04>;
				clocks = <0x02 0x29 0x02 0xd1>;
				clock-names = "core", "comp";
				#address-cells = <0x01>;
				#size-cells = <0x00>;
				status = "disabled";
				phandle = <0xe3>;
			};

			spi@15000 {
				compatible = "amlogic,meson-g12a-spicc";
				reg = <0x00 0x15000 0x00 0x44>;
				interrupts = <0x00 0x5a 0x04>;
				clocks = <0x02 0x2f 0x02 0xd5>;
				clock-names = "core", "comp";
				#address-cells = <0x01>;
				#size-cells = <0x00>;
				status = "disabled";
				phandle = <0xe4>;
			};
		};

		aobus@ff800000 {
			compatible = "simple-bus";
			reg = <0x00 0xff800000 0x00 0xb000>;
			#address-cells = <0x02>;
			#size-cells = <0x02>;
			ranges = <0x00 0x00 0x00 0xff800000 0x00 0xb000>;
			phandle = <0xe5>;

			cpu_version {
				reg = <0x00 0x220 0x00 0x04>;
			};

			clock-controller@0 {
				compatible = "amlogic,g12a-aoclkc";
				#clock-cells = <0x01>;
				#reset-cells = <0x01>;
				reg = <0x00 0x00 0x00 0x320>;
				phandle = <0xe6>;
			};

			pwm@7000 {
				compatible = "amlogic,g12a-ao-pwm";
				reg = <0x00 0x7000 0x00 0x20>;
				#pwm-cells = <0x03>;
				clocks = <0x1f 0x1f 0x1f 0x1f>;
				clock-names = "clkin0", "clkin1", "clkin2", "clkin3";
				status = "disabled";
				phandle = <0xe7>;
			};

			pwm@2000 {
				compatible = "amlogic,g12a-ao-pwm";
				reg = <0x00 0x2000 0x00 0x20>;
				#pwm-cells = <0x03>;
				clocks = <0x1f 0x1f 0x1f 0x1f>;
				clock-names = "clkin0", "clkin1", "clkin2", "clkin3";
				status = "okay";
				phandle = <0x5f>;
			};

			i2c@5000 {
				compatible = "amlogic,meson-g12a-i2c";
				status = "disabled";
				reg = <0x00 0x5000 0x00 0x20>;
				interrupts = <0x00 0xc3 0x01 0x00 0xc9 0x01>;
				#address-cells = <0x01>;
				#size-cells = <0x00>;
				clocks = <0x02 0x2a>;
				clock-names = "clk_i2c";
				phandle = <0xe8>;
			};

			i2c_slave@6000 {
				compatible = "amlogic, meson-i2c-slave";
				status = "disabled";
				reg = <0x00 0x6000 0x00 0x20>;
				interrupts = <0x00 0xc2 0x01>;
				pinctrl-names = "default";
				pinctrl-0 = <0x26>;
				phandle = <0xe9>;
			};

			serial@3000 {
				compatible = "amlogic, meson-uart";
				reg = <0x00 0x3000 0x00 0x18>;
				interrupts = <0x00 0xc1 0x01>;
				status = "okay";
				clocks = <0x1f>;
				clock-names = "clk_uart";
				xtal_tick_en = <0x02>;
				fifosize = <0x40>;
				pinctrl-names = "default";
				support-sysrq = <0x00>;
				phandle = <0xea>;
			};

			serial@4000 {
				compatible = "amlogic, meson-uart";
				reg = <0x00 0x4000 0x00 0x18>;
				interrupts = <0x00 0xc5 0x01>;
				status = "disabled";
				clocks = <0x1f>;
				clock-names = "clk_uart";
				fifosize = <0x40>;
				pinctrl-names = "default";
				pinctrl-0 = <0x27>;
				phandle = <0xeb>;
			};

			meson-irblaster@14c {
				compatible = "amlogic, meson_irblaster";
				reg = <0x00 0x14c 0x00 0x10 0x00 0x40 0x00 0x04>;
				#irblaster-cells = <0x02>;
				pinctrl-names = "default";
				pinctrl-0 = <0x28>;
				interrupts = <0x00 0xc6 0x01>;
				status = "okay";
				phandle = <0xec>;
			};
		};

		periphs@ff634400 {
			compatible = "simple-bus";
			reg = <0x00 0xff634400 0x00 0x400>;
			#address-cells = <0x02>;
			#size-cells = <0x02>;
			ranges = <0x00 0x00 0x00 0xff634400 0x00 0x400>;
			phandle = <0xed>;
		};

		hiubus@ff63c000 {
			compatible = "simple-bus";
			reg = <0x00 0xff63c000 0x00 0x2000>;
			#address-cells = <0x02>;
			#size-cells = <0x02>;
			ranges = <0x00 0x00 0x00 0xff63c000 0x00 0x2000>;
			phandle = <0xee>;

			clock-controller@0 {
				compatible = "amlogic,g12a-clkc";
				#clock-cells = <0x01>;
				reg = <0x00 0x00 0x00 0x320>;
				phandle = <0x02>;
			};
		};

		ion_dev {
			compatible = "amlogic, ion_dev";
			memory-region = <0x29 0x2a>;
		};

		audiobus@0xff642000 {
			compatible = "amlogic, audio-controller", "simple-bus";
			reg = <0x00 0xff642000 0x00 0x2000>;
			#address-cells = <0x02>;
			#size-cells = <0x02>;
			ranges = <0x00 0x00 0x00 0xff642000 0x00 0x2000>;
			phandle = <0xef>;

			audio_clocks {
				compatible = "amlogic, g12a-audio-clocks";
				#clock-cells = <0x01>;
				reg = <0x00 0x00 0x00 0xb0>;
				phandle = <0x2b>;
			};

			ddr_manager {
				compatible = "amlogic, g12a-audio-ddr-manager";
				interrupts = <0x00 0x94 0x01 0x00 0x95 0x01 0x00 0x96 0x01 0x00 0x98 0x01 0x00 0x99 0x01 0x00 0x9a 0x01>;
				interrupt-names = "toddr_a", "toddr_b", "toddr_c", "frddr_a", "frddr_b", "frddr_c";
			};

			tdma {
				compatible = "amlogic, g12a-snd-tdma";
				#sound-dai-cells = <0x00>;
				dai-tdm-lane-slot-mask-in = <0x00 0x01>;
				dai-tdm-oe-lane-slot-mask-out = <0x01 0x00>;
				dai-tdm-clk-sel = <0x00>;
				clocks = <0x2b 0x17 0x02 0x0c>;
				clock-names = "mclk", "clk_srcpll";
				pinctrl-names = "tdm_pins";
				pinctrl-0 = <0x2c 0x2d>;
				phandle = <0x99>;
			};

			tdmb {
				compatible = "amlogic, g12a-snd-tdmb";
				#sound-dai-cells = <0x00>;
				dai-tdm-lane-slot-mask-in = <0x00 0x01 0x00 0x00>;
				dai-tdm-lane-slot-mask-out = <0x01 0x00 0x00 0x00>;
				dai-tdm-clk-sel = <0x01>;
				clocks = <0x2b 0x18 0x02 0x0d 0x02 0x0c 0x2b 0x1e>;
				clock-names = "mclk", "clk_srcpll", "samesource_srcpll", "samesource_clk";
				pinctrl-names = "tdm_pins";
				pinctrl-0 = <0x2e 0x2f 0x30>;
				mclk_pad = <0x00>;
				samesource_sel = <0x03>;
				start_clk_enable = <0x01>;
				clk_tuning_enable = <0x01>;
				phandle = <0x9b>;
			};

			tdmc {
				compatible = "amlogic, g12a-snd-tdmc";
				#sound-dai-cells = <0x00>;
				dai-tdm-lane-slot-mask-out = <0x01 0x01 0x01 0x01>;
				dai-tdm-clk-sel = <0x02>;
				clocks = <0x2b 0x19 0x02 0x0e>;
				clock-names = "mclk", "clk_srcpll";
				i2s2hdmi = <0x01>;
				phandle = <0x9c>;
			};

			tdm@3 {
				compatible = "amlogic, g12a-snd-tdmlb";
				#sound-dai-cells = <0x00>;
				dai-tdm-lane-lb-slot-mask-in = <0x01 0x00 0x00 0x00>;
				dai-tdm-clk-sel = <0x01>;
				clocks = <0x2b 0x18 0x02 0x0d>;
				clock-names = "mclk", "clk_srcpll";
				lb-src-sel = <0x01>;
				status = "disabled";
				phandle = <0xf0>;
			};

			i2s2hdmi {
				compatible = "amlogic, g12a-snd-tdmc";
				#sound-dai-cells = <0x00>;
				dai-tdm-lane-slot-mask-out = <0x01 0x01 0x01 0x01>;
				dai-tdm-clk-sel = <0x02>;
				clocks = <0x2b 0x19 0x02 0x0e>;
				clock-names = "mclk", "clk_srcpll";
				i2s2hdmi = <0x01>;
				status = "disabled";
				phandle = <0xf1>;
			};

			spdif {
				compatible = "amlogic, g12a-snd-spdif-a";
				#sound-dai-cells = <0x00>;
				clocks = <0x02 0x0c 0x02 0x04 0x2b 0x10 0x2b 0x11 0x2b 0x1d 0x2b 0x1e>;
				clock-names = "sysclk", "fixed_clk", "gate_spdifin", "gate_spdifout", "clk_spdifin", "clk_spdifout";
				interrupts = <0x00 0x97 0x01>;
				interrupt-names = "irq_spdifin";
				pinctrl-names = "spdif_pins", "spdif_pins_mute";
				pinctrl-0 = <0x31>;
				pinctrl-1 = <0x32>;
				status = "okay";
				clk_tuning_enable = <0x01>;
				phandle = <0x9e>;
			};

			spdif_b {
				compatible = "amlogic, g12a-snd-spdif-b";
				#sound-dai-cells = <0x00>;
				clocks = <0x02 0x0e 0x2b 0x15 0x2b 0x21>;
				clock-names = "sysclk", "gate_spdifout", "clk_spdifout";
				status = "okay";
				phandle = <0x9f>;
			};

			pdm {
				compatible = "amlogic, g12a-snd-pdm";
				#sound-dai-cells = <0x00>;
				clocks = <0x2b 0x01 0x02 0x03 0x02 0x0f 0x2b 0x1f 0x2b 0x20>;
				clock-names = "gate", "sysclk_srcpll", "dclk_srcpll", "pdm_dclk", "pdm_sysclk";
				pinctrl-names = "pdm_pins";
				pinctrl-0 = <0x33>;
				filter_mode = <0x01>;
				status = "okay";
				phandle = <0x9d>;
			};

			loopback@0 {
				compatible = "amlogic, g12a-loopback";
				#sound-dai-cells = <0x00>;
				clocks = <0x2b 0x01 0x02 0x03 0x02 0x0f 0x2b 0x1f 0x2b 0x20 0x02 0x0c 0x2b 0x17>;
				clock-names = "pdm_gate", "pdm_sysclk_srcpll", "pdm_dclk_srcpll", "pdm_dclk", "pdm_sysclk", "tdminlb_mpll", "tdminlb_mclk";
				datain_src = <0x04>;
				datain_chnum = <0x04>;
				datain_chmask = <0x0f>;
				datain-lane-mask-in = <0x01 0x00 0x01 0x00>;
				mclk-fs = <0x100>;
				datalb_src = <0x01>;
				datalb_chnum = <0x02>;
				datalb_chmask = <0x03>;
				datalb-lane-mask-in = <0x01 0x00 0x00 0x00>;
				status = "okay";
				phandle = <0xa0>;
			};

			resample {
				compatible = "amlogic, g12a-resample";
				clocks = <0x02 0x0f 0x2b 0x1c 0x2b 0x24>;
				clock-names = "resample_pll", "resample_src", "resample_clk";
				resample_module = <0x04>;
				status = "okay";
				phandle = <0xf2>;
			};

			pwrdet {
				compatible = "amlogic, g12a-power-detect";
				interrupts = <0x00 0x9b 0x01>;
				interrupt-names = "pwrdet_irq";
				pwrdet_src = <0x04>;
				hi_th = <0x70000>;
				lo_th = <0x16000>;
				status = "disabled";
				phandle = <0xf3>;
			};
		};
	};

	rc@0xff808040 {
		compatible = "amlogic, aml_remote";
		dev_name = "meson-remote";
		reg = <0x00 0xff808040 0x00 0x44 0x00 0xff808000 0x00 0x20>;
		status = "okay";
		protocol = <0x01>;
		led_blink = <0x01>;
		led_blink_frq = <0x64>;
		interrupts = <0x00 0xc4 0x01>;
		pinctrl-names = "default";
		pinctrl-0 = <0x34>;
		map = <0x35>;
		max_frame_time = <0xc8>;
		phandle = <0xf4>;
	};

	serial@ffd24000 {
		compatible = "amlogic, meson-uart";
		reg = <0x00 0xffd24000 0x00 0x18>;
		interrupts = <0x00 0x1a 0x01>;
		status = "okay";
		clocks = <0x1f 0x02 0x2e>;
		clock-names = "clk_uart", "clk_gate";
		fifosize = <0x80>;
		pinctrl-names = "default";
		pinctrl-0 = <0x36>;
		phandle = <0xf5>;
	};

	serial@ffd23000 {
		compatible = "amlogic, meson-uart";
		reg = <0x00 0xffd23000 0x00 0x18>;
		interrupts = <0x00 0x4b 0x01>;
		status = "disabled";
		clocks = <0x1f 0x02 0x3c>;
		clock-names = "clk_uart", "clk_gate";
		fifosize = <0x40>;
		pinctrl-names = "default";
		pinctrl-0 = <0x37>;
		phandle = <0xf6>;
	};

	serial@ffd22000 {
		compatible = "amlogic, meson-uart";
		reg = <0x00 0xffd22000 0x00 0x18>;
		interrupts = <0x00 0x5d 0x01>;
		status = "disabled";
		clocks = <0x1f 0x02 0x3c>;
		clock-names = "clk_uart", "clk_gate";
		fifosize = <0x40>;
		pinctrl-names = "default";
		pinctrl-0 = <0x38>;
		phandle = <0xf7>;
	};

	pcieA@fc000000 {
		compatible = "amlogic, amlogic-pcie-v2", "snps,dw-pcie";
		reg = <0x00 0xfc000000 0x00 0x400000 0x00 0xff648000 0x00 0x2000 0x00 0xfc400000 0x00 0x200000 0x00 0xff646000 0x00 0x2000 0x00 0xffd01080 0x00 0x10>;
		reg-names = "elbi", "cfg", "config", "phy", "reset";
		interrupts = <0x00 0xdd 0x00>;
		#interrupt-cells = <0x01>;
		bus-range = <0x00 0xff>;
		#address-cells = <0x03>;
		#size-cells = <0x02>;
		interrupt-map-mask = <0x00 0x00 0x00 0x00>;
		interrupt-map = <0x00 0x00 0x00 0x00 0x01 0x00 0xdf 0x01>;
		device_type = "pci";
		ranges = <0x81000000 0x00 0x00 0x00 0xfc600000 0x00 0x100000 0x82000000 0x00 0xfc700000 0x00 0xfc700000 0x00 0x1900000>;
		num-lanes = <0x01>;
		pcie-num = <0x01>;
		clocks = <0x02 0x18 0x02 0x3f 0x02 0x42>;
		clock-names = "pcie_refpll", "pcie", "pcie_phy";
		gpio-type = <0x02>;
		pcie-apb-rst-bit = <0x0f>;
		pcie-phy-rst-bit = <0x0e>;
		pcie-ctrl-a-rst-bit = <0x0c>;
		status = "disable";
		reset-gpio = <0x23 0x49 0x00>;
		phandle = <0xf8>;
	};

	amhdmitx {
		compatible = "amlogic, amhdmitx";
		dev_name = "amhdmitx";
		status = "okay";
		vend-data = <0x39>;
		pinctrl-names = "default", "hdmitx_i2c";
		pinctrl-0 = <0x3a 0x3b>;
		pinctrl-1 = <0x3c 0x3d>;
		clocks = <0x02 0x55 0x02 0x4e 0x02 0x4f 0x02 0x95 0x02 0x8c>;
		clock-names = "venci_top_gate", "venci_0_gate", "venci_1_gate", "hdmi_vapb_clk", "hdmi_vpu_clk";
		interrupts = <0x00 0x39 0x01 0x00 0x03 0x01>;
		interrupt-names = "hdmitx_hpd", "viu1_vsync";
		ic_type = <0x0a>;
		dongle_mode = <0x00>;
		phandle = <0xf9>;

		vend_data {
			vendor_name = "Amlogic";
			product_desc = "MBox Meson Ref";
			vendor_id = <0x00>;
			phandle = <0x39>;
		};
	};

	amprime_sl {
		compatible = "amlogic, prime_sl_g12";
		dev_name = "amprime_sl";
		status = "disabled";
		phandle = <0xfa>;
	};

	aocec {
		compatible = "amlogic, aocec-g12a";
		device_name = "aocec";
		status = "okay";
		vendor_name = "Amlogic";
		vendor_id = <0x00>;
		product_desc = "G12A";
		cec_osd_string = "AML_MBOX";
		cec_version = <0x05>;
		port_num = <0x01>;
		output = <0x01>;
		ee_cec;
		arc_port_mask = <0x02>;
		interrupts = <0x00 0xcb 0x01 0x00 0xc7 0x01>;
		interrupt-names = "hdmi_aocecb", "hdmi_aocec";
		pinctrl-names = "default", "hdmitx_aocecb", "cec_pin_sleep";
		pinctrl-0 = <0x3e>;
		pinctrl-1 = <0x3f>;
		pinctrl-2 = <0x3f>;
		reg = <0x00 0xff80023c 0x00 0x04 0x00 0xff800000 0x00 0x400 0x00 0xff634400 0x00 0x26>;
		reg-names = "ao_exit", "ao", "periphs";
		phandle = <0xfb>;
	};

	vdin0 {
		compatible = "amlogic, vdin";
		dev_name = "vdin0";
		status = "disable";
		reserve-iomap = "true";
		flag_cma = <0x00>;
		interrupts = <0x00 0x53 0x01>;
		rdma-irq = <0x02>;
		vdin_id = <0x00>;
		cma_size = <0x14>;
		tv_bit_mode = <0x01>;
		phandle = <0xfc>;
	};

	vdin1 {
		compatible = "amlogic, vdin";
		dev_name = "vdin1";
		status = "okay";
		reserve-iomap = "true";
		flag_cma = <0x00>;
		interrupts = <0x00 0x55 0x01>;
		rdma-irq = <0x04>;
		vdin_id = <0x01>;
		memory-region = <0x40>;
		tv_bit_mode = <0x01>;
		phandle = <0xfd>;
	};

	vout_sys {
		compatible = "amlogic, vout_sys_serve";
		status = "okay";
		reg = <0x00 0xff8000ac 0x00 0x04>;
		phandle = <0xfe>;
	};

	vout {
		compatible = "amlogic, vout";
		dev_name = "vout";
		status = "okay";
		fr_policy = <0x00>;
	};

	vout2 {
		compatible = "amlogic, vout2";
		dev_name = "vout";
		status = "okay";
		clocks = <0x02 0xc4 0x02 0xc9>;
		clock-names = "vpu_clkc0", "vpu_clkc";
		fr_policy = <0x00>;
	};

	dummy_venc {
		compatible = "amlogic, dummy_venc";
		status = "okay";
		clocks = <0x02 0x56 0x02 0x50 0x02 0x51 0x02 0x55 0x02 0x4e 0x02 0x4f 0x02 0x5d 0x02 0x5f>;
		clock-names = "encp_top_gate", "encp_int_gate0", "encp_int_gate1", "venci_top_gate", "enci_int_gate0", "enci_int_gate1", "encl_top_gate", "encl_int_gate";
		phandle = <0xff>;
	};

	vdac {
		compatible = "amlogic, vdac-g12a";
		status = "okay";
	};

	canvas {
		compatible = "amlogic, meson, canvas";
		dev_name = "amlogic-canvas";
		status = "okay";
		reg = <0x00 0xff638000 0x00 0x2000>;
		phandle = <0x100>;
	};

	ge2d {
		compatible = "amlogic, ge2d-g12a";
		dev_name = "ge2d";
		status = "okay";
		interrupts = <0x00 0x92 0x01>;
		interrupt-names = "ge2d";
		clocks = <0x02 0x95 0x02 0x3d 0x02 0x96>;
		clock-names = "clk_vapb_0", "clk_ge2d", "clk_ge2d_gate";
		reg = <0x00 0xff940000 0x00 0x10000>;
	};

	meson-amvideom {
		compatible = "amlogic, amvideom";
		dev_name = "amvideom";
		status = "okay";
		interrupts = <0x00 0x03 0x01>;
		interrupt-names = "vsync";
	};

	codec_io {
		compatible = "amlogic, codec_io";
		status = "okay";
		#address-cells = <0x02>;
		#size-cells = <0x02>;
		ranges;
		phandle = <0x101>;

		io_cbus_base {
			reg = <0x00 0xffd00000 0x00 0x100000>;
		};

		io_dos_base {
			reg = <0x00 0xff620000 0x00 0x10000>;
		};

		io_hiubus_base {
			reg = <0x00 0xff63c000 0x00 0x2000>;
		};

		io_aobus_base {
			reg = <0x00 0xff800000 0x00 0x10000>;
		};

		io_vcbus_base {
			reg = <0x00 0xff900000 0x00 0x40000>;
		};

		io_dmc_base {
			reg = <0x00 0xff638000 0x00 0x2000>;
		};

		io_efuse_base {
			reg = <0x00 0xff630000 0x00 0x2000>;
		};
	};

	mesonstream {
		compatible = "amlogic, codec, streambuf";
		dev_name = "mesonstream";
		status = "okay";
		clocks = <0x02 0x40 0x02 0x39 0x02 0x43 0x02 0x22 0x02 0x0b 0x02 0xa5 0x02 0xae 0x02 0xb7 0x02 0xc0>;
		clock-names = "parser_top", "demux", "ahbarb0", "vdec", "clk_81", "clk_vdec_mux", "clk_hcodec_mux", "clk_hevc_mux", "clk_hevcb_mux";
	};

	vdec {
		compatible = "amlogic, vdec";
		dev_name = "vdec.0";
		status = "okay";
		interrupts = <0x00 0x03 0x01 0x00 0x17 0x01 0x00 0x20 0x01 0x00 0x2b 0x01 0x00 0x2c 0x01 0x00 0x2d 0x01>;
		interrupt-names = "vsync", "demux", "parser", "mailbox_0", "mailbox_1", "mailbox_2";
	};

	vcodec_dec {
		compatible = "amlogic, vcodec-dec";
		dev_name = "aml-vcodec-dec";
		status = "okay";
	};

	video_composer {
		compatible = "amlogic, video_composer";
		dev_name = "video_composer";
		status = "okay";
	};

	amvenc_avc {
		compatible = "amlogic, amvenc_avc";
		dev_name = "amvenc_avc";
		status = "okay";
		interrupts = <0x00 0x2d 0x01>;
		interrupt-names = "mailbox_2";
	};

	hevc_enc {
		compatible = "cnm, HevcEnc";
		dev_name = "HevcEnc";
		status = "okay";
		interrupts = <0x00 0xbb 0x01>;
		interrupt-names = "wave420l_irq";
		#address-cells = <0x02>;
		#size-cells = <0x02>;
		ranges;

		io_reg_base {
			reg = <0x00 0xff610000 0x00 0x4000>;
		};
	};

	rdma {
		compatible = "amlogic, meson, rdma";
		dev_name = "amlogic-rdma";
		status = "okay";
		interrupts = <0x00 0x59 0x01>;
		interrupt-names = "rdma";
	};

	meson-fb {
		compatible = "amlogic, meson-g12a";
		memory-region = <0x41>;
		dev_name = "meson-fb";
		status = "okay";
		interrupts = <0x00 0x03 0x01 0x00 0x38 0x01 0x00 0x59 0x01>;
		interrupt-names = "viu-vsync", "viu2-vsync", "rdma";
		display_mode_default = "1080p60hz";
		scale_mode = <0x01>;
		display_size_default = <0x780 0x438 0x780 0x870 0x20>;
		clocks = <0x02 0xc9>;
		clock-names = "vpu_clkc";
		mem_size = <0x800000 0x1980000 0x100000 0x100000 0x800000>;
		logo_addr = "0x7f800000";
		mem_alloc = <0x00>;
		pxp_mode = <0x00>;
		phandle = <0x102>;
	};

	emmc@ffe07000 {
		status = "okay";
		compatible = "amlogic, meson-mmc-g12a";
		reg = <0x00 0xffe07000 0x00 0x800>;
		interrupts = <0x00 0xbf 0x01>;
		pinctrl-names = "emmc_clk_cmd_pins", "emmc_all_pins";
		pinctrl-0 = <0x42>;
		pinctrl-1 = <0x43 0x44>;
		clocks = <0x02 0x35 0x02 0x72 0x02 0x02 0x02 0x05 0x1f>;
		clock-names = "core", "clkin0", "clkin1", "clkin2", "xtal";
		bus-width = <0x08>;
		cap-sd-highspeed;
		cap-mmc-highspeed;
		max-frequency = <0xbebc200>;
		non-removable;
		disable-wp;
		phandle = <0x103>;

		emmc {
			pinname = "emmc";
			ocr_avail = <0x200080>;
			tx_delay = <0x00>;
			co_phase = <0x03>;
			calc_f = <0x01>;
			max_req_size = <0x20000>;
			gpio_dat3 = <0x23 0x1d 0x00>;
			hw_reset = <0x23 0x26 0x00>;
			card_type = <0x01>;
			caps = "MMC_CAP_8_BIT_DATA", "MMC_CAP_MMC_HIGHSPEED", "MMC_CAP_SD_HIGHSPEED", "MMC_CAP_NONREMOVABLE", "MMC_CAP_HW_RESET", "MMC_CAP_ERASE", "MMC_CAP_CMD23";
			caps2 = "MMC_CAP2_HS200";
			f_min = <0x61a80>;
			f_max = <0xbebc200>;
		};
	};

	sd1@ffe05000 {
		status = "disabled";
		compatible = "amlogic, meson-mmc-g12a";
		reg = <0x00 0xffe05000 0x00 0x800>;
		interrupts = <0x00 0xbe 0x01>;
		pinctrl-names = "sd_all_pins", "sd_clk_cmd_pins", "sd_1bit_pins", "sd_clk_cmd_uart_pins", "sd_1bit_uart_pins", "sd_to_ao_uart_pins", "ao_to_sd_uart_pins", "sd_to_ao_jtag_pins", "ao_to_sd_jtag_pins";
		pinctrl-0 = <0x45>;
		pinctrl-1 = <0x46>;
		pinctrl-2 = <0x47>;
		pinctrl-3 = <0x48 0x46 0x49>;
		pinctrl-4 = <0x48 0x47 0x49>;
		pinctrl-5 = <0x45 0x4a>;
		pinctrl-6 = <0x48 0x49>;
		pinctrl-7 = <0x45 0x4a>;
		pinctrl-8 = <0x48 0x49>;
		clocks = <0x02 0x34 0x02 0x6e 0x02 0x02 0x02 0x05 0x1f>;
		clock-names = "core", "clkin0", "clkin1", "clkin2", "xtal";
		bus-width = <0x04>;
		cap-sd-highspeed;
		cap-mmc-highspeed;
		max-frequency = <0x5f5e100>;
		disable-wp;
		phandle = <0x104>;

		sd {
			pinname = "sd";
			ocr_avail = <0x200080>;
			max_req_size = <0x20000>;
			gpio_dat3 = <0x23 0x2d 0x00>;
			jtag_pin = <0x23 0x2a 0x00>;
			gpio_cd = <0x23 0x30 0x00>;
			card_type = <0x05>;
			caps = "MMC_CAP_4_BIT_DATA", "MMC_CAP_MMC_HIGHSPEED", "MMC_CAP_SD_HIGHSPEED";
			f_min = <0x61a80>;
			f_max = <0x2faf080>;
		};
	};

	sd2@ffe05000 {
		status = "disabled";
		compatible = "amlogic, meson-mmc-g12a";
		reg = <0x00 0xffe05000 0x00 0x800>;
		interrupts = <0x00 0xbe 0x04>;
		pinctrl-names = "sd_all_pins", "sd_clk_cmd_pins", "sd_1bit_pins", "sd_clk_cmd_uart_pins", "sd_1bit_uart_pins", "sd_to_ao_uart_pins", "ao_to_sd_uart_pins", "sd_to_ao_jtag_pins", "ao_to_sd_jtag_pins", "sdio_noclr_all_pins", "sdio_noclr_clk_cmd_pins", "sdio_all_pins", "sdio_clk_cmd_pins";
		pinctrl-0 = <0x4b 0x45>;
		pinctrl-1 = <0x4b 0x46>;
		pinctrl-2 = <0x4b 0x47>;
		pinctrl-3 = <0x4b 0x48 0x46 0x49>;
		pinctrl-4 = <0x4b 0x48 0x47 0x49>;
		pinctrl-5 = <0x4b 0x45 0x4a>;
		pinctrl-6 = <0x4c 0x48 0x4d 0x49>;
		pinctrl-7 = <0x4c 0x4e 0x4a>;
		pinctrl-8 = <0x4c 0x48 0x4d 0x49>;
		pinctrl-9 = <0x4d 0x4c 0x4f>;
		pinctrl-10 = <0x4d 0x4c 0x50>;
		pinctrl-11 = <0x4e 0x4c 0x4f>;
		pinctrl-12 = <0x4e 0x4c 0x50>;
		clocks = <0x02 0x34 0x02 0x6e 0x02 0x02 0x02 0x05 0x1f>;
		clock-names = "core", "clkin0", "clkin1", "clkin2", "xtal";
		bus-width = <0x04>;
		cap-sd-highspeed;
		cap-mmc-highspeed;
		max-frequency = <0x5f5e100>;
		disable-wp;
		phandle = <0x105>;

		sd {
			pinname = "sd";
			ocr_avail = <0x200080>;
			max_req_size = <0x20000>;
			gpio_dat3 = <0x23 0x2d 0x00>;
			jtag_pin = <0x23 0x2a 0x00>;
			gpio_cd = <0x23 0x30 0x00>;
			card_type = <0x05>;
			caps = "MMC_CAP_4_BIT_DATA", "MMC_CAP_MMC_HIGHSPEED", "MMC_CAP_SD_HIGHSPEED";
			f_min = <0x61a80>;
			f_max = <0x2faf080>;
		};

		sdio {
			pinname = "sdio";
			ocr_avail = <0x200080>;
			max_req_size = <0x20000>;
			card_type = <0x03>;
			caps = "MMC_CAP_4_BIT_DATA", "MMC_CAP_MMC_HIGHSPEED", "MMC_CAP_SD_HIGHSPEED", "MMC_CAP_NONREMOVABLE", "MMC_CAP_UHS_SDR12", "MMC_CAP_UHS_SDR25", "MMC_CAP_UHS_SDR50", "MMC_CAP_UHS_SDR104", "MMC_PM_KEEP_POWER", "MMC_CAP_SDIO_IRQ";
			f_min = <0x61a80>;
			f_max = <0xbebc200>;
		};
	};

	sd3@ffe05000 {
		status = "disabled";
		compatible = "amlogic, meson-mmc-g12a";
		reg = <0x00 0xffe05000 0x00 0x800>;
		interrupts = <0x00 0xbe 0x04>;
		pinctrl-names = "sdio_all_pins", "sdio_clk_cmd_pins";
		pinctrl-0 = <0x4c 0x4f>;
		pinctrl-1 = <0x4c 0x50>;
		clocks = <0x02 0x34 0x02 0x6e 0x02 0x02 0x02 0x05 0x1f>;
		clock-names = "core", "clkin0", "clkin1", "clkin2", "xtal";
		bus-width = <0x04>;
		cap-sd-highspeed;
		cap-mmc-highspeed;
		max-frequency = <0x5f5e100>;
		disable-wp;
		phandle = <0x106>;

		sdio {
			pinname = "sdio";
			ocr_avail = <0x200080>;
			max_req_size = <0x20000>;
			card_type = <0x03>;
		};
	};

	sdio@ffe03000 {
		status = "disabled";
		compatible = "amlogic, meson-mmc-g12a";
		reg = <0x00 0xffe03000 0x00 0x800>;
		interrupts = <0x00 0xbd 0x04>;
		pinctrl-names = "sdio_all_pins", "sdio_clk_cmd_pins";
		pinctrl-0 = <0x51>;
		pinctrl-1 = <0x52>;
		clocks = <0x02 0x33 0x02 0x6a 0x02 0x02 0x02 0x05 0x1f>;
		clock-names = "core", "clkin0", "clkin1", "clkin2", "xtal";
		bus-width = <0x04>;
		cap-sd-highspeed;
		cap-mmc-highspeed;
		max-frequency = <0x5f5e100>;
		disable-wp;
		phandle = <0x107>;

		sdio {
			pinname = "sdio";
			ocr_avail = <0x200080>;
			max_req_size = <0x400>;
			card_type = <0x03>;
			dmode = "pio";
			caps = "MMC_CAP_4_BIT_DATA", "MMC_CAP_MMC_HIGHSPEED", "MMC_CAP_SD_HIGHSPEED", "MMC_CAP_NONREMOVABLE", "MMC_CAP_UHS_SDR12", "MMC_CAP_UHS_SDR25", "MMC_CAP_UHS_SDR50", "MMC_CAP_UHS_SDR104", "MMC_PM_KEEP_POWER", "MMC_CAP_SDIO_IRQ";
			f_min = <0x61a80>;
			f_max = <0xbebc200>;
		};
	};

	nfc@0 {
		compatible = "amlogic, aml_mtd_nand";
		dev_name = "mtdnand";
		status = "disabled";
		reg = <0x00 0xffe07800 0x00 0x200>;
		interrupts = <0x00 0x22 0x01>;
		pinctrl-names = "nand_rb_mod", "nand_norb_mod", "nand_cs_only";
		pinctrl-0 = <0x53>;
		pinctrl-1 = <0x53>;
		pinctrl-2 = <0x54>;
		clocks = <0x02 0x35 0x02 0x02>;
		clock-names = "gate", "fdiv2pll";
		device_id = <0x00>;
		bl_mode = <0x01>;
		fip_copies = <0x04>;
		fip_size = <0x200000>;
		nand_clk_ctrl = <0xffe07000>;
		plat-names = "bootloader", "nandnormal";
		plat-num = <0x02>;
		plat-part-0 = <0x55>;
		plat-part-1 = <0x56>;
		phandle = <0x108>;

		bootloader {
			enable_pad = "ce0";
			busy_pad = "rb0";
			timming_mode = "mode5";
			bch_mode = "bch8_1k";
			t_rea = <0x14>;
			t_rhoh = <0x0f>;
			chip_num = <0x01>;
			part_num = <0x00>;
			rb_detect = <0x01>;
			phandle = <0x55>;
		};

		nandnormal {
			enable_pad = "ce0";
			busy_pad = "rb0";
			timming_mode = "mode5";
			bch_mode = "bch8_1k";
			plane_mode = "twoplane";
			t_rea = <0x14>;
			t_rhoh = <0x0f>;
			chip_num = <0x02>;
			part_num = <0x03>;
			partition = <0x57>;
			rb_detect = <0x01>;
			phandle = <0x56>;
		};

		nand_partition {
			phandle = <0x57>;

			tpl {
				offset = <0x00 0x00>;
				size = <0x00 0x00>;
			};

			logo {
				offset = <0x00 0x00>;
				size = <0x00 0x200000>;
			};

			recovery {
				offset = <0x00 0x00>;
				size = <0x00 0x1000000>;
			};

			boot {
				offset = <0x00 0x00>;
				size = <0x00 0x1000000>;
			};

			system {
				offset = <0x00 0x00>;
				size = <0x00 0x4000000>;
			};

			data {
				offset = <0xffffffff 0xffffffff>;
				size = <0x00 0x00>;
			};
		};
	};

	meson-cooldev@0 {
		status = "okay";
		compatible = "amlogic, meson-cooldev";
		device_name = "mcooldev";
		phandle = <0x109>;

		cooling_devices {

			cpufreq_cool_cluster0 {
				min_state = <0xf4240>;
				dyn_coeff = <0x73>;
				cluster_id = <0x00>;
				node_name = "cpufreq_cool0";
				device_type = "cpufreq";
			};

			cpucore_cool_cluster0 {
				min_state = <0x01>;
				dyn_coeff = <0x00>;
				cluster_id = <0x00>;
				node_name = "cpucore_cool0";
				device_type = "cpucore";
			};

			gpufreq_cool {
				min_state = <0x190>;
				dyn_coeff = <0x166>;
				gpu_pp = <0x02>;
				cluster_id = <0x00>;
				node_name = "gpufreq_cool0";
				device_type = "gpufreq";
			};

			gpucore_cool {
				min_state = <0x01>;
				dyn_coeff = <0x00>;
				cluster_id = <0x00>;
				node_name = "gpucore_cool0";
				device_type = "gpucore";
			};
		};

		cpufreq_cool0 {
			#cooling-cells = <0x02>;
			phandle = <0x5a>;
		};

		cpucore_cool0 {
			#cooling-cells = <0x02>;
			phandle = <0x5b>;
		};

		gpufreq_cool0 {
			#cooling-cells = <0x02>;
			phandle = <0x5c>;
		};

		gpucore_cool0 {
			#cooling-cells = <0x02>;
			phandle = <0x5d>;
		};
	};

	thermal-zones {

		soc_thermal {
			polling-delay = <0x3e8>;
			polling-delay-passive = <0x64>;
			sustainable-power = <0x5b4>;
			thermal-sensors = <0x58 0x00>;
			phandle = <0x10a>;

			trips {

				trip-point@0 {
					temperature = <0x11170>;
					hysteresis = <0x1388>;
					type = "passive";
					phandle = <0x10b>;
				};

				trip-point@1 {
					temperature = <0x14c08>;
					hysteresis = <0x1388>;
					type = "passive";
					phandle = <0x59>;
				};

				trip-point@2 {
					temperature = <0x17318>;
					hysteresis = <0x1388>;
					type = "hot";
					phandle = <0x10c>;
				};

				trip-point@3 {
					temperature = <0x1adb0>;
					hysteresis = <0x3e8>;
					type = "critical";
					phandle = <0x10d>;
				};
			};

			cooling-maps {

				cpufreq_cooling_map {
					trip = <0x59>;
					cooling-device = <0x5a 0x00 0x04>;
					contribution = <0x400>;
				};

				cpucore_cooling_map {
					trip = <0x59>;
					cooling-device = <0x5b 0x00 0x03>;
					contribution = <0x400>;
				};

				gpufreq_cooling_map {
					trip = <0x59>;
					cooling-device = <0x5c 0x00 0x04>;
					contribution = <0x400>;
				};

				gpucore_cooling_map {
					trip = <0x59>;
					cooling-device = <0x5d 0x00 0x02>;
					contribution = <0x400>;
				};
			};
		};

		ddr_thermal {
			polling-delay = <0x3e8>;
			polling-delay-passive = <0x64>;
			sustainable-power = <0x866>;
			thermal-sensors = <0x5e 0x01>;
			phandle = <0x10e>;

			trips {

				trip-point@0 {
					temperature = <0x11170>;
					hysteresis = <0x1388>;
					type = "passive";
					phandle = <0x10f>;
				};

				trip-point@1 {
					temperature = <0x14c08>;
					hysteresis = <0x1388>;
					type = "passive";
					phandle = <0x110>;
				};

				trip-point@2 {
					temperature = <0x17318>;
					hysteresis = <0x1388>;
					type = "hot";
					phandle = <0x111>;
				};

				trip-point@3 {
					temperature = <0x1adb0>;
					hysteresis = <0x3e8>;
					type = "critical";
					phandle = <0x112>;
				};
			};
		};
	};

	aml_snd_iomap {
		compatible = "amlogic, snd-iomap";
		status = "okay";
		#address-cells = <0x02>;
		#size-cells = <0x02>;
		ranges;

		pdm_bus {
			reg = <0x00 0xff640000 0x00 0x2000>;
		};

		audiobus_base {
			reg = <0x00 0xff642000 0x00 0x2000>;
		};

		audiolocker_base {
			reg = <0x00 0xff64a000 0x00 0x2000>;
		};

		eqdrc_base {
			reg = <0x00 0xff642800 0x00 0x1800>;
		};

		reset_base {
			reg = <0x00 0xffd01000 0x00 0x1000>;
		};
	};

	pwmao_d-regulator {
		compatible = "pwm-regulator";
		pwms = <0x5f 0x01 0x4e2 0x00>;
		regulator-name = "vddcpu0";
		regulator-min-microvolt = <0xb0068>;
		regulator-max-microvolt = <0xf9830>;
		regulator-always-on;
		max-duty-cycle = <0x4e2>;
		voltage-table = <0xf9830 0x00 0xf6d38 0x03 0xf4628 0x06 0xf1f18 0x0a 0xef808 0x0d 0xed0f8 0x10 0xea9e8 0x14 0xe82d8 0x17 0xe5bc8 0x1a 0xe34b8 0x1e 0xe0da8 0x21 0xde698 0x24 0xdbf88 0x28 0xd9878 0x2b 0xd7168 0x2e 0xd4a58 0x32 0xd2348 0x35 0xcfc38 0x38 0xcd528 0x3c 0xcae18 0x3f 0xc8708 0x43 0xc5ff8 0x46 0xc38e8 0x49 0xc11d8 0x4c 0xbeac8 0x50 0xbc3b8 0x53 0xb9ca8 0x56 0xb7598 0x5a 0xb4e88 0x5d 0xb2778 0x60 0xb0068 0x64>;
		status = "okay";
		phandle = <0x1a>;
	};

	ddr_bandwidth {
		compatible = "amlogic, ddr-bandwidth";
		status = "okay";
		reg = <0x00 0xff638000 0x00 0x100 0x00 0xff638c00 0x00 0x100>;
		sec_base = <0xff639000>;
		interrupts = <0x00 0x34 0x01>;
		interrupt-names = "ddr_bandwidth";
	};

	dmc_monitor {
		compatible = "amlogic, dmc_monitor";
		status = "okay";
		reg_base = <0xff639000>;
		interrupts = <0x00 0x33 0x01>;
	};

	defendkey {
		compatible = "amlogic, defendkey";
		reg = <0x00 0xff630218 0x00 0x04>;
		mem_size = <0x00 0x100000>;
		status = "okay";
		phandle = <0x113>;
	};

	aml_dma {
		compatible = "amlogic,aml_txlx_dma";
		reg = <0x00 0xff63e000 0x00 0x48>;
		interrupts = <0x00 0xb4 0x01>;

		aml_aes {
			compatible = "amlogic,aes_g12a_dma";
			dev_name = "aml_aes_dma";
			status = "okay";
		};

		aml_sha {
			compatible = "amlogic,sha_dma";
			dev_name = "aml_sha_dma";
			status = "okay";
		};

		aml_tdes {
			compatible = "amlogic,tdes_dma";
			dev_name = "aml_tdes_dma";
			status = "okay";
		};
	};

	rng {
		compatible = "amlogic,meson-rng";
		status = "okay";
		#address-cells = <0x02>;
		#size-cells = <0x02>;
		reg = <0x00 0xff630218 0x00 0x04>;
		quality = [03 e8];
	};

	efuse {
		compatible = "amlogic, efuse";
		read_cmd = <0x82000030>;
		write_cmd = <0x82000031>;
		get_max_cmd = <0x82000033>;
		key = <0x60>;
		clocks = <0x02 0x61>;
		clock-names = "efuse_clk";
		status = "disabled";
		phandle = <0x114>;
	};

	cpu_ver_name {
		compatible = "amlogic, cpu-major-id-g12a";
	};

	firmware {

		android {
			compatible = "android,firmware";

			vbmeta {
				compatible = "android,vbmeta";
				parts = "vbmeta,boot,system,vendor,oem";
				by_name_prefix = "/dev/block";
			};
		};
	};

	partitions {
		parts = <0x10>;
		part-0 = <0x61>;
		part-1 = <0x62>;
		part-2 = <0x63>;
		part-3 = <0x64>;
		part-4 = <0x65>;
		part-5 = <0x66>;
		part-6 = <0x67>;
		part-7 = <0x68>;
		part-8 = <0x69>;
		part-9 = <0x6a>;
		part-10 = <0x6b>;
		part-11 = <0x6c>;
		part-12 = <0x6d>;
		part-13 = <0x6e>;
		part-14 = <0x6f>;
		part-15 = <0x70>;
		phandle = <0x115>;

		logo {
			pname = "logo";
			size = <0x00 0x800000>;
			mask = <0x01>;
			phandle = <0x61>;
		};

		recovery {
			pname = "recovery";
			size = <0x00 0x1800000>;
			mask = <0x01>;
			phandle = <0x62>;
		};

		tee {
			pname = "tee";
			size = <0x00 0x2000000>;
			mask = <0x01>;
			phandle = <0x6c>;
		};

		factory {
			pname = "factory";
			size = <0x00 0x800000>;
			mask = <0x11>;
			phandle = <0x6d>;
		};

		misc {
			pname = "misc";
			size = <0x00 0x800000>;
			mask = <0x01>;
			phandle = <0x63>;
		};

		conf {
			pname = "conf";
			size = <0x00 0x400000>;
			mask = <0x01>;
			phandle = <0x64>;
		};

		dtbo {
			pname = "dtbo";
			size = <0x00 0x800000>;
			mask = <0x01>;
			phandle = <0x65>;
		};

		cri_data {
			pname = "cri_data";
			size = <0x00 0x800000>;
			mask = <0x02>;
			phandle = <0x66>;
		};

		oem {
			pname = "oem";
			size = <0x00 0x1000000>;
			mask = <0x01>;
			phandle = <0x69>;
		};

		metadata {
			pname = "metadata";
			size = <0x00 0x1000000>;
			mask = <0x01>;
			phandle = <0x6a>;
		};

		vbmeta {
			pname = "vbmeta";
			size = <0x00 0x200000>;
			mask = <0x01>;
			phandle = <0x6b>;
		};

		param {
			pname = "param";
			size = <0x00 0x1000000>;
			mask = <0x02>;
			phandle = <0x67>;
		};

		boot {
			pname = "boot";
			size = <0x00 0x1000000>;
			mask = <0x01>;
			phandle = <0x68>;
		};

		super {
			pname = "super";
			size = <0x00 0x70800000>;
			mask = <0x01>;
			phandle = <0x6e>;
		};

		cache {
			pname = "cache";
			size = <0x00 0x3e800000>;
			mask = <0x02>;
			phandle = <0x6f>;
		};

		userdata {
			pname = "userdata";
			size = <0xffffffff 0xffffffff>;
			mask = <0x04>;
			phandle = <0x70>;
		};
	};

	aliases {
		serial0 = "/soc/aobus@ff800000/serial@3000";
		serial1 = "/serial@ffd24000";
		serial2 = "/serial@ffd23000";
		serial3 = "/serial@ffd22000";
		serial4 = "/soc/aobus@ff800000/serial@4000";
		tsensor0 = "/p_tsensor@ff634594";
		tsensor1 = "/d_tsensor@ff800228";
		i2c0 = "/soc/cbus@ffd00000/i2c@1f000";
		i2c1 = "/soc/cbus@ffd00000/i2c@1e000";
		i2c2 = "/soc/cbus@ffd00000/i2c@1d000";
		i2c3 = "/soc/cbus@ffd00000/i2c@1c000";
		i2c4 = "/soc/aobus@ff800000/i2c@5000";
	};

	memory@00000000 {
		device_type = "memory";
		linux,usable-memory = <0x00 0x00 0x00 0x80000000>;
	};

	reserved-memory {
		#address-cells = <0x02>;
		#size-cells = <0x02>;
		ranges;

		ramoops@0x07400000 {
			compatible = "ramoops";
			reg = <0x00 0x7400000 0x00 0x100000>;
			record-size = <0x20000>;
			console-size = <0x40000>;
			ftrace-size = <0x80000>;
			pmsg-size = <0x20000>;
		};

		linux,secmon {
			compatible = "shared-dma-pool";
			reusable;
			size = <0x00 0x400000>;
			alignment = <0x00 0x400000>;
			alloc-ranges = <0x00 0x5000000 0x00 0x400000>;
			phandle = <0x1b>;
		};

		linux,secos {
			status = "disable";
			compatible = "amlogic, aml_secos_memory";
			reg = <0x00 0x5300000 0x00 0x2000000>;
			no-map;
			phandle = <0x116>;
		};

		linux,meson-fb {
			compatible = "shared-dma-pool";
			reusable;
			size = <0x00 0x800000>;
			alignment = <0x00 0x400000>;
			alloc-ranges = <0x00 0x7f800000 0x00 0x800000>;
			phandle = <0x41>;
		};

		linux,ion-dev {
			compatible = "shared-dma-pool";
			reusable;
			size = <0x00 0x8000000>;
			alignment = <0x00 0x400000>;
			phandle = <0x29>;
		};

		linux,ion-fb {
			compatible = "amlogic, ion-fb-mem";
			reusable;
			size = <0x00 0x3800000>;
			alignment = <0x00 0x400000>;
			phandle = <0x2a>;
		};

		linux,di_cma {
			compatible = "shared-dma-pool";
			status = "disable";
			reusable;
			size = <0x00 0x00>;
			alignment = <0x00 0x400000>;
			phandle = <0x77>;
		};

		linux,ppmgr {
			compatible = "shared-dma-pool";
			size = <0x00 0x00>;
			phandle = <0x76>;
		};

		linux,codec_mm_cma {
			compatible = "shared-dma-pool";
			reusable;
			size = <0x00 0x1b000000>;
			alignment = <0x00 0x400000>;
			linux,contiguous-region;
			phandle = <0x73>;
		};

		linux,codec_mm_reserved {
			compatible = "amlogic, codec-mm-reserved";
			size = <0x00 0x00>;
			alignment = <0x00 0x100000>;
			phandle = <0x74>;
		};

		linux,vdin1_cma {
			compatible = "shared-dma-pool";
			reusable;
			size = <0x00 0x1400000>;
			alignment = <0x00 0x400000>;
			phandle = <0x40>;
		};
	};

	cma_shrinker {
		compatible = "amlogic, cma-shrinker";
		status = "okay";
		adj = <0x00 0x64 0xc8 0xfa 0x384 0x3b6>;
		free = <0x2000 0x3000 0x4000 0x6000 0x7000 0x8000>;
	};

	dummy-battery {
		compatible = "amlogic, dummy-battery";
		status = "disabled";
		phandle = <0x117>;
	};

	dummy-charger {
		compatible = "amlogic, dummy-charger";
		status = "disabled";
		phandle = <0x118>;
	};

	gpioleds {
		compatible = "gpio-leds";
		status = "disabled";

		net_red {
			label = "net_red";
			default-state = "on";
		};

		net_green {
			label = "net_green";
			default-state = "on";
		};

		remote_led {
			label = "remote_led";
			default-state = "off";
			linux,default-trigger = "rc_feedback";
		};

		sys_led {
			label = "sys_led";
			gpios = <0x71 0x0b 0x01>;
			default-state = "on";
		};
	};

	cvbsout {
		compatible = "amlogic, cvbsout-g12a";
		dev_name = "cvbsout";
		status = "okay";
		clocks = <0x02 0x55 0x02 0x4e 0x02 0x4f 0x02 0x57>;
		clock-names = "venci_top_gate", "venci_0_gate", "venci_1_gate", "vdac_clk_gate";
		clk_path = <0x00>;
		performance_pal = <0x1bf0 0x09 0x1b56 0x333 0x1b12 0x8080 0x1b05 0xfd 0x1c59 0x732 0xffff 0x00>;
		performance_ntsc = <0x1bf0 0x09 0x1b56 0x333 0x1b12 0x9c00 0x1b03 0x01 0x1b04 0x05 0x1b05 0xfc 0x1b06 0x08 0x1c59 0xfc48 0xffff 0x00>;
		performance_sarft = <0x1bf0 0x09 0x1b56 0x333 0x1b12 0x00 0x1b05 0x09 0x1c59 0xfc48 0xffff 0x00>;
		performance_revB_telecom = <0x1bf0 0x09 0x1b56 0x546 0x1b12 0x8080 0x1b05 0x09 0x1c59 0xf850 0xffff 0x00>;
	};

	bt-dev {
		compatible = "amlogic, bt-dev";
		dev_name = "bt-dev";
		status = "okay";
		gpio_en = <0x23 0x53 0x00>;
		gpio_hostwake = <0x23 0x55 0x00>;
		power_down_disable = <0x01>;
	};

	wifi {
		compatible = "amlogic, aml_wifi";
		dev_name = "aml_wifi";
		status = "okay";
		irq_trigger_type = "GPIO_IRQ_LOW";
		power_on_pin = <0x23 0x48 0x00>;
		power_on_pin2 = <0x23 0x49 0x00>;
	};

	wifi_pwm_conf {
		phandle = <0x119>;

		pwm_channel1_conf {
			pwms = <0x72 0x00 0x774d 0x00>;
			duty-cycle = <0x3ba6>;
			times = <0x0a>;
		};

		pwm_channel2_conf {
			pwms = <0x72 0x02 0x7724 0x00>;
			duty-cycle = <0x3b92>;
			times = <0x0c>;
		};
	};

	linux,picdec {
		compatible = "shared-dma-pool";
		reusable;
		size = <0x00>;
		alignment = <0x00>;
		linux,contiguous-region;
		phandle = <0x75>;
	};

	codec_mm {
		compatible = "amlogic, codec, mm";
		memory-region = <0x73 0x74>;
		dev_name = "codec_mm";
		status = "okay";
	};

	picdec {
		compatible = "amlogic, picdec";
		memory-region = <0x75>;
		dev_name = "picdec";
		status = "okay";
	};

	gpio_keypad {
		compatible = "amlogic, gpio_keypad";
		status = "okay";
		scan_period = <0x14>;
		key_num = <0x01>;
		key_name = "power";
		key_code = <0xf9>;
		key-gpios = <0x71 0x03 0x00>;
		detect_mode = <0x00>;
	};

	ppmgr {
		compatible = "amlogic, ppmgr";
		memory-region = <0x76>;
		dev_name = "ppmgr";
		status = "okay";
	};

	multi-di {
		compatible = "amlogic, dim-g12a";
		status = "okay";
		flag_cma = <0x04>;
		memory-region = <0x77>;
		interrupts = <0x00 0x2e 0x01 0x00 0x28 0x01>;
		interrupt-names = "pre_irq", "post_irq";
		clocks = <0x02 0x9b 0x02 0x9c>;
		clock-names = "vpu_clkb_tmp_composite", "vpu_clkb_composite";
		clock-range = <0x14e 0x14e>;
		buffer-size = <0x3e2c40>;
		post-wr-support = <0x01>;
		nr10bit-support = <0x01>;
		nrds-enable = <0x01>;
		pps-enable = <0x01>;
	};

	deinterlace {
		compatible = "amlogic, deinterlace";
		status = "disable";
		flag_cma = <0x01>;
		interrupts = <0x00 0x2e 0x01 0x00 0x28 0x01>;
		interrupt-names = "pre_irq", "post_irq";
		clocks = <0x02 0x9b 0x02 0x9c>;
		clock-names = "vpu_clkb_tmp_composite", "vpu_clkb_composite";
		clock-range = <0x14e 0x29b>;
		buffer-size = <0x3e2c40>;
		post-wr-support = <0x01>;
		nr10bit-support = <0x01>;
		nrds-enable = <0x01>;
		pps-enable = <0x01>;
	};

	dvb-extern {
		compatible = "amlogic, dvb-extern";
		dev_name = "dvb-extern";
		status = "okay";
		fe_num = <0x01>;
		fe0_demod = "mxl248";
		fe0_i2c_adap_id = <0x78>;
		fe0_demod_i2c_addr = <0x60>;
		fe0_reset_value = <0x00>;
		fe0_reset_gpio = <0x23 0x09 0x00>;
		fe0_ts = <0x00>;
	};

	demux {
		compatible = "amlogic, dvb-demux";
		dev_name = "dvb-demux";
		status = "okay";
		ts1 = "serial";
		ts1_control = <0x800>;
		ts1_invert = <0x00>;
		interrupts = <0x00 0x17 0x01 0x00 0x05 0x01 0x00 0x15 0x01 0x00 0x13 0x01 0x00 0x19 0x01 0x00 0x12 0x01 0x00 0x18 0x01>;
		interrupt-names = "demux0_irq", "demux1_irq", "demux2_irq", "dvr0_irq", "dvr1_irq", "dvrfill0_fill", "dvrfill1_flush";
		pinctrl-names = "s_ts1";
		pinctrl-0 = <0x79>;
		clocks = <0x02 0x39 0x02 0x43 0x02 0x40>;
		clock-names = "demux", "ahbarb0", "parser_top";
	};

	ionvideo {
		compatible = "amlogic, ionvideo";
		dev_name = "ionvideo";
		status = "okay";
	};

	amlvideo2_0 {
		compatible = "amlogic, amlvideo2";
		dev_name = "amlvideo2";
		status = "okay";
		amlvideo2_id = <0x00>;
		cma_mode = <0x01>;
	};

	amlvideo2_1 {
		compatible = "amlogic, amlvideo2";
		dev_name = "amlvideo2";
		status = "okay";
		amlvideo2_id = <0x01>;
		cma_mode = <0x01>;
	};

	unifykey {
		compatible = "amlogic, unifykey";
		status = "ok";
		unifykey-num = <0x19>;
		unifykey-index-0 = <0x7a>;
		unifykey-index-1 = <0x7b>;
		unifykey-index-2 = <0x7c>;
		unifykey-index-3 = <0x7d>;
		unifykey-index-4 = <0x7e>;
		unifykey-index-5 = <0x7f>;
		unifykey-index-6 = <0x80>;
		unifykey-index-7 = <0x81>;
		unifykey-index-8 = <0x82>;
		unifykey-index-9 = <0x83>;
		unifykey-index-10 = <0x84>;
		unifykey-index-11 = <0x85>;
		unifykey-index-12 = <0x86>;
		unifykey-index-13 = <0x87>;
		unifykey-index-14 = <0x88>;
		unifykey-index-15 = <0x89>;
		unifykey-index-16 = <0x8a>;
		unifykey-index-17 = <0x8b>;
		unifykey-index-18 = <0x8c>;
		unifykey-index-19 = <0x8d>;
		unifykey-index-20 = <0x8e>;
		unifykey-index-21 = <0x8f>;
		unifykey-index-22 = <0x90>;
		unifykey-index-23 = <0x91>;
		unifykey-index-24 = <0x92>;

		key_0 {
			key-name = "usid";
			key-device = "normal";
			key-permit = "read", "write", "del";
			phandle = <0x7a>;
		};

		key_1 {
			key-name = "mac";
			key-device = "normal";
			key-permit = "read", "write", "del";
			phandle = <0x7b>;
		};

		key_2 {
			key-name = "hdcp";
			key-device = "secure";
			key-type = "sha1";
			key-permit = "read", "write", "del";
			phandle = <0x7c>;
		};

		key_3 {
			key-name = "secure_boot_set";
			key-device = "efuse";
			key-permit = "write";
			phandle = <0x7d>;
		};

		key_4 {
			key-name = "mac_bt";
			key-device = "normal";
			key-permit = "read", "write", "del";
			key-type = "mac";
			phandle = <0x7e>;
		};

		key_5 {
			key-name = "mac_wifi";
			key-device = "normal";
			key-permit = "read", "write", "del";
			key-type = "mac";
			phandle = <0x7f>;
		};

		key_6 {
			key-name = "hdcp2_tx";
			key-device = "normal";
			key-permit = "read", "write", "del";
			phandle = <0x80>;
		};

		key_7 {
			key-name = "hdcp2_rx";
			key-device = "normal";
			key-permit = "read", "write", "del";
			phandle = <0x81>;
		};

		key_8 {
			key-name = "widevinekeybox";
			key-device = "secure";
			key-permit = "read", "write", "del";
			phandle = <0x82>;
		};

		key_9 {
			key-name = "deviceid";
			key-device = "normal";
			key-permit = "read", "write", "del";
			phandle = <0x83>;
		};

		key_10 {
			key-name = "hdcp22_fw_private";
			key-device = "secure";
			key-permit = "read", "write", "del";
			phandle = <0x84>;
		};

		key_11 {
			key-name = "PlayReadykeybox25";
			key-device = "secure";
			key-permit = "read", "write", "del";
			phandle = <0x85>;
		};

		key_12 {
			key-name = "prpubkeybox";
			key-device = "secure";
			key-permit = "read", "write", "del";
			phandle = <0x86>;
		};

		key_13 {
			key-name = "prprivkeybox";
			key-device = "secure";
			key-permit = "read", "write", "del";
			phandle = <0x87>;
		};

		key_14 {
			key-name = "attestationkeybox";
			key-device = "secure";
			key-permit = "read", "write", "del";
			phandle = <0x88>;
		};

		key_15 {
			key-name = "netflix_mgkid";
			key-device = "secure";
			key-permit = "read", "write", "del";
			phandle = <0x89>;
		};

		key_16 {
			key-name = "attestationdevidbox";
			key-device = "secure";
			key-permit = "read", "write", "del";
			phandle = <0x8a>;
		};

		key_17 {
			key-name = "oemkey";
			key-device = "normal";
			key-permit = "read", "write", "del";
			phandle = <0x8b>;
		};

		key_18 {
			key-name = "KEY_PROVISION_XXX";
			key-device = "provision";
			key-permit = "read", "write", "del";
			phandle = <0x8c>;
		};

		key_19 {
			key-name = "ultra-key-s905x2-0x01000605";
			key-device = "efuse";
			key-permit = "write";
			phandle = <0x8d>;
		};

		key_20 {
			key-name = "Licensekey";
			key-device = "normal";
			key-permit = "read", "write";
			phandle = <0x8e>;
		};

		key_21 {
			key-name = "mac_en";
			key-device = "normal";
			key-permit = "read", "write";
			phandle = <0x8f>;
		};

		key_22 {
			key-name = "stbid_en";
			key-device = "normal";
			key-permit = "read", "write";
			phandle = <0x90>;
		};

		key_23 {
			key-name = "Market";
			key-device = "normal";
			key-permit = "read", "write";
			phandle = <0x91>;
		};

		key_24 {
			key-name = "Operator";
			key-device = "normal";
			key-permit = "read", "write";
			phandle = <0x92>;
		};
	};

	efusekey {
		keynum = <0x04>;
		key0 = <0x93>;
		key1 = <0x94>;
		key2 = <0x95>;
		key3 = <0x96>;
		phandle = <0x60>;

		key_0 {
			keyname = "mac";
			offset = <0x00>;
			size = <0x06>;
			phandle = <0x93>;
		};

		key_1 {
			keyname = "mac_bt";
			offset = <0x06>;
			size = <0x06>;
			phandle = <0x94>;
		};

		key_2 {
			keyname = "mac_wifi";
			offset = <0x0c>;
			size = <0x06>;
			phandle = <0x95>;
		};

		key_3 {
			keyname = "usid";
			offset = <0x12>;
			size = <0x10>;
			phandle = <0x96>;
		};
	};

	amlvecm {
		compatible = "amlogic, vecm";
		dev_name = "aml_vecm";
		status = "okay";
		gamma_en = <0x00>;
		wb_en = <0x00>;
		cm_en = <0x00>;
		tx_op_color_primary = <0x00>;
	};

	amdolby_vision {
		compatible = "amlogic, dolby_vision_g12a";
		dev_name = "aml_amdolby_vision_driver";
		status = "okay";
		tv_mode = <0x00>;
	};

	dummy {
		#sound-dai-cells = <0x00>;
		compatible = "amlogic, aml_dummy_codec";
		status = "okay";
		phandle = <0x9a>;
	};

	t9015 {
		#sound-dai-cells = <0x00>;
		compatible = "amlogic, aml_codec_T9015";
		reg = <0x00 0xff632000 0x00 0x2000>;
		is_auge_used = <0x01>;
		tdmout_index = <0x01>;
		status = "okay";
		phandle = <0x97>;
	};

	eqdrc {
		eqdrc_module = <0x01>;
		lane_mask = <0x01>;
		channel_mask = <0x03>;
		phandle = <0x98>;
	};

	auge_sound {
		compatible = "amlogic, g12a-sound-card";
		aml-audio-card,name = "AML-AUGESOUND";
		aml-audio-card,aux-devs = <0x97>;
		avout_mute-gpios = <0x71 0x02 0x00>;
		aml-audio-card,effect = <0x98>;

		aml-audio-card,dai-link@0 {
			format = "dsp_a";
			mclk-fs = <0x200>;
			suffix-name = "alsaPORT-pcm";

			cpu {
				sound-dai = <0x99>;
				dai-tdm-slot-tx-mask = <0x01 0x01 0x01 0x01 0x01 0x01 0x01 0x01>;
				dai-tdm-slot-rx-mask = <0x01 0x01 0x01 0x01 0x01 0x01 0x01 0x01>;
				dai-tdm-slot-num = <0x08>;
				dai-tdm-slot-width = <0x20>;
				system-clock-frequency = <0x1770000>;
				phandle = <0x11a>;
			};

			codec {
				sound-dai = <0x9a 0x9a>;
				phandle = <0x11b>;
			};
		};

		aml-audio-card,dai-link@1 {
			format = "i2s";
			mclk-fs = <0x100>;
			bitclock-master = <0x9b>;
			frame-master = <0x9b>;
			suffix-name = "alsaPORT-i2s";

			cpu {
				sound-dai = <0x9b>;
				dai-tdm-slot-tx-mask = <0x01 0x01>;
				dai-tdm-slot-rx-mask = <0x01 0x01>;
				dai-tdm-slot-num = <0x02>;
				dai-tdm-slot-width = <0x20>;
				system-clock-frequency = <0xbb8000>;
			};

			codec {
				sound-dai = <0x9a 0x9a 0x97>;
				phandle = <0x11c>;
			};
		};

		aml-audio-card,dai-link@2 {
			format = "i2s";
			mclk-fs = <0x100>;
			bitclock-master = <0x9c>;
			frame-master = <0x9c>;
			suffix-name = "alsaPORT-i2s2hdmi";

			cpu {
				sound-dai = <0x9c>;
				dai-tdm-slot-tx-mask = <0x01 0x01>;
				dai-tdm-slot-rx-mask = <0x01 0x01>;
				dai-tdm-slot-num = <0x02>;
				dai-tdm-slot-width = <0x20>;
				system-clock-frequency = <0xbb8000>;
			};

			codec {
				sound-dai = <0x9a 0x9a>;
			};
		};

		aml-audio-card,dai-link@3 {
			mclk-fs = <0x40>;
			suffix-name = "alsaPORT-pdm-builtinmic";

			cpu {
				sound-dai = <0x9d>;
			};

			codec {
				sound-dai = <0x9a>;
			};
		};

		aml-audio-card,dai-link@4 {
			mclk-fs = <0x80>;
			continuous-clock;
			suffix-name = "alsaPORT-spdif";

			cpu {
				sound-dai = <0x9e>;
				system-clock-frequency = <0x5dc000>;
			};

			codec {
				sound-dai = <0x9a>;
			};
		};

		aml-audio-card,dai-link@5 {
			mclk-fs = <0x80>;
			continuous-clock;
			suffix-name = "alsaPORT-spdifb";

			cpu {
				sound-dai = <0x9f>;
				system-clock-frequency = <0x5dc000>;
			};

			codec {
				sound-dai = <0x9a>;
			};
		};

		aml-audio-card,dai-link@6 {
			mclk-fs = <0x100>;
			continuous-clock;
			suffix-name = "alsaPORT-loopback";

			cpu {
				sound-dai = <0xa0>;
				system-clock-frequency = <0xbb8000>;
			};

			codec {
				sound-dai = <0x9a>;
			};
		};
	};

	locker {
		compatible = "amlogic, audiolocker";
		clocks = <0x2b 0x22 0x2b 0x23 0x2b 0x1a 0x2b 0x1b 0x02 0x0d 0x02 0x0e>;
		clock-names = "lock_out", "lock_in", "out_src", "in_src", "out_calc", "in_ref";
		interrupts = <0x00 0x01 0x01>;
		interrupt-names = "irq";
		frequency = <0x2ebae40>;
		dividor = <0x31>;
		status = "okay";
		phandle = <0x11d>;
	};

	cpu_opp_table0 {
		compatible = "operating-points-v2";
		opp-shared;
		phandle = <0x19>;

		opp00 {
			opp-hz = <0x00 0x5f5e100>;
			opp-microvolt = <0xb2778>;
		};

		opp01 {
			opp-hz = <0x00 0xee6b280>;
			opp-microvolt = <0xb2778>;
		};

		opp02 {
			opp-hz = <0x00 0x1dcd6500>;
			opp-microvolt = <0xb2778>;
		};

		opp03 {
			opp-hz = <0x00 0x27c19cc0>;
			opp-microvolt = <0xb2778>;
		};

		opp04 {
			opp-hz = <0x00 0x3b9aca00>;
			opp-microvolt = <0xb2778>;
		};

		opp05 {
			opp-hz = <0x00 0x47868c00>;
			opp-microvolt = <0xb9ca8>;
		};

		opp06 {
			opp-hz = <0x00 0x5353c980>;
			opp-microvolt = <0xc11d8>;
		};

		opp07 {
			opp-hz = <0x00 0x5a1f4a00>;
			opp-microvolt = <0xcae18>;
		};

		opp08 {
			opp-hz = <0x00 0x5fd82200>;
			opp-microvolt = <0xd4a58>;
		};

		opp09 {
			opp-hz = <0x00 0x6590fa00>;
			opp-microvolt = <0xe0da8>;
		};

		opp10 {
			opp-hz = <0x00 0x6b49d200>;
			opp-microvolt = <0xef808>;
		};
	};

	cpufreq-meson {
		compatible = "amlogic, cpufreq-meson";
		pinctrl-names = "default";
		pinctrl-0 = <0xa1>;
		status = "okay";
	};

	__symbols__ {
		gpu = "/bifrost";
		dvfs125_cfg = "/bifrost/clk125_cfg";
		dvfs250_cfg = "/bifrost/dvfs250_cfg";
		dvfs285_cfg = "/bifrost/dvfs285_cfg";
		dvfs400_cfg = "/bifrost/dvfs400_cfg";
		dvfs500_cfg = "/bifrost/dvfs500_cfg";
		dvfs666_cfg = "/bifrost/dvfs666_cfg";
		dvfs800_cfg = "/bifrost/dvfs800_cfg";
		dvfs850_cfg = "/bifrost/dvfs850_cfg";
		custom_maps = "/custom_maps";
		map_0 = "/custom_maps/map_0";
		map_1 = "/custom_maps/map_1";
		map_2 = "/custom_maps/map_2";
		map_3 = "/custom_maps/map_3";
		map_4 = "/custom_maps/map_4";
		map_5 = "/custom_maps/map_5";
		map_6 = "/custom_maps/map_6";
		map_7 = "/custom_maps/map_7";
		map_8 = "/custom_maps/map_8";
		map_9 = "/custom_maps/map_9";
		map_10 = "/custom_maps/map_10";
		map_11 = "/custom_maps/map_11";
		cpus = "/cpus";
		cluster0 = "/cpus/cpu-map/cluster0";
		CPU0 = "/cpus/cpu@0";
		CPU1 = "/cpus/cpu@1";
		CPU2 = "/cpus/cpu@2";
		CPU3 = "/cpus/cpu@3";
		CPU_SLEEP_0 = "/cpus/idle-states/cpu-sleep-0";
		gic = "/interrupt-controller@2c001000";
		mailbox = "/mhu@c883c400";
		xtal = "/xtal-clk";
		ethmac = "/ethernet@ff3f0000";
		pinctrl_aobus = "/pinctrl@ff800014";
		gpio_ao = "/pinctrl@ff800014/ao-bank@ff800014";
		sd_to_ao_uart_clr_pins = "/pinctrl@ff800014/sd_to_ao_uart_clr_pins";
		sd_to_ao_uart_pins = "/pinctrl@ff800014/sd_to_ao_uart_pins";
		ao_uart_pins = "/pinctrl@ff800014/ao_uart";
		ao_b_uart_pins = "/pinctrl@ff800014/ao_b_uart";
		ao_i2c_master_pins1 = "/pinctrl@ff800014/ao_i2c_pins1";
		ao_i2c_master_pins2 = "/pinctrl@ff800014/ao_i2c_pins2";
		ao_i2c_slave_pins = "/pinctrl@ff800014/ao_i2c_slave_pins";
		pwm_ao_a_pins = "/pinctrl@ff800014/pwm_ao_a";
		pwm_ao_a_hiz_pins = "/pinctrl@ff800014/pwm_ao_a_hiz";
		pwm_ao_b_pins = "/pinctrl@ff800014/pwm_ao_b";
		pwm_ao_c_pins1 = "/pinctrl@ff800014/pwm_ao_c_pins1";
		pwm_ao_c_pins2 = "/pinctrl@ff800014/pwm_ao_c_pins2";
		pwm_ao_c_hiz_pins = "/pinctrl@ff800014/pwm_ao_c_hiz";
		pwm_ao_d_pins1 = "/pinctrl@ff800014/pwm_ao_d_pins1";
		pwm_ao_d_pins2 = "/pinctrl@ff800014/pwm_ao_d_pins2";
		pwm_ao_d_pins3 = "/pinctrl@ff800014/pwm_ao_d_pins3";
		aocec_a = "/pinctrl@ff800014/ao_ceca";
		aocec_b = "/pinctrl@ff800014/ao_cecb";
		jtag_apao_pins = "/pinctrl@ff800014/jtag_apao_pin";
		remote_pins = "/pinctrl@ff800014/remote_pin";
		irblaster_pins = "/pinctrl@ff800014/irblaster_pin";
		dvb_s_ts0_pins = "/pinctrl@ff800014/dvb_s_ts0_pins";
		pinctrl_periphs = "/pinctrl@ff634480";
		gpio = "/pinctrl@ff634480/banks@ff6346c0";
		emmc_clk_cmd_pins = "/pinctrl@ff634480/emmc_clk_cmd_pins";
		emmc_conf_pull_up = "/pinctrl@ff634480/emmc_conf_pull_up";
		emmc_conf_pull_done = "/pinctrl@ff634480/emmc_conf_pull_done";
		sd_clk_cmd_pins = "/pinctrl@ff634480/sd_clk_cmd_pins";
		sd_all_pins = "/pinctrl@ff634480/sd_all_pins";
		sd_1bit_pins = "/pinctrl@ff634480/sd_1bit_pins";
		sd_clr_all_pins = "/pinctrl@ff634480/sd_clr_all_pins";
		sd_clr_noall_pins = "/pinctrl@ff634480/sd_clr_noall_pins";
		ao_to_sd_uart_pins = "/pinctrl@ff634480/ao_to_sd_uart_pins";
		sdio_clk_cmd_pins = "/pinctrl@ff634480/sdio_clk_cmd_pins";
		sdio_all_pins = "/pinctrl@ff634480/sdio_all_pins";
		sdio_x_clk_cmd_pins = "/pinctrl@ff634480/sdio_x_clk_cmd_pins";
		sdio_x_all_pins = "/pinctrl@ff634480/sdio_x_all_pins";
		sdio_x_en_pins = "/pinctrl@ff634480/sdio_x_en_pins";
		sdio_x_clr_pins = "/pinctrl@ff634480/sdio_x_clr_pins";
		all_nand_pins = "/pinctrl@ff634480/all_nand_pins";
		nand_cs_pins = "/pinctrl@ff634480/nand_cs";
		i2c0_master_pins1 = "/pinctrl@ff634480/i2c0_pins1";
		i2c0_master_pins2 = "/pinctrl@ff634480/i2c0_pins2";
		i2c0_master_pins3 = "/pinctrl@ff634480/i2c0_pins3";
		i2c1_master_pins1 = "/pinctrl@ff634480/i2c1_pins1";
		i2c1_master_pins2 = "/pinctrl@ff634480/i2c1_pins2";
		i2c1_master_pins3 = "/pinctrl@ff634480/i2c1_pins3";
		i2c2_master_pins1 = "/pinctrl@ff634480/i2c2_pins1";
		i2c2_master_pins2 = "/pinctrl@ff634480/i2c2_pins2";
		i2c3_master_pins1 = "/pinctrl@ff634480/i2c3_pins1";
		i2c3_master_pins2 = "/pinctrl@ff634480/i2c3_pins2";
		pwm_a_pins = "/pinctrl@ff634480/pwm_a";
		pwm_b_pins1 = "/pinctrl@ff634480/pwm_b_pins1";
		pwm_b_pins2 = "/pinctrl@ff634480/pwm_b_pins2";
		pwm_c_pins1 = "/pinctrl@ff634480/pwm_c_pins1";
		pwm_c_pins2 = "/pinctrl@ff634480/pwm_c_pins2";
		pwm_c_pins3 = "/pinctrl@ff634480/pwm_c_pins3";
		pwm_d_pins1 = "/pinctrl@ff634480/pwm_d_pins1";
		pwm_d_pins2 = "/pinctrl@ff634480/pwm_d_pins2";
		pwm_e_pins = "/pinctrl@ff634480/pwm_e";
		pwm_f_pins1 = "/pinctrl@ff634480/pwm_f_pins1";
		pwm_f_pins2 = "/pinctrl@ff634480/pwm_f_pins2";
		spicc0_pins_x = "/pinctrl@ff634480/spicc0_pins_x";
		spicc0_pins_c = "/pinctrl@ff634480/spicc0_pins_c";
		spicc1_pins = "/pinctrl@ff634480/spicc1_pins";
		a_uart_pins = "/pinctrl@ff634480/a_uart";
		b_uart_pins = "/pinctrl@ff634480/b_uart";
		c_uart_pins = "/pinctrl@ff634480/c_uart";
		hdmitx_hpd = "/pinctrl@ff634480/hdmitx_hpd";
		hdmitx_hpd_gpio = "/pinctrl@ff634480/hdmitx_hpd_gpio";
		hdmitx_ddc = "/pinctrl@ff634480/hdmitx_ddc";
		eecec_a = "/pinctrl@ff634480/ee_ceca";
		eecec_b = "/pinctrl@ff634480/ee_cecb";
		internal_eth_pins = "/pinctrl@ff634480/internal_eth_pins";
		internal_gpio_pins = "/pinctrl@ff634480/internal_gpio_pins";
		external_eth_pins = "/pinctrl@ff634480/external_eth_pins";
		jtag_apee_pins = "/pinctrl@ff634480/jtag_apee_pin";
		tdmout_a = "/pinctrl@ff634480/tdmout_a";
		tdmin_a = "/pinctrl@ff634480/tdmin_a";
		tdmb_mclk = "/pinctrl@ff634480/tdmb_mclk";
		tdmout_b = "/pinctrl@ff634480/tdmout_b";
		tdmin_b = "/pinctrl@ff634480/tdmin_b";
		tdmc_mclk = "/pinctrl@ff634480/tdmc_mclk";
		tdmout_c = "/pinctrl@ff634480/tdmout_c";
		tdmin_c = "/pinctrl@ff634480/tdmin_c";
		spdifin = "/pinctrl@ff634480/spdifin";
		spdifout = "/pinctrl@ff634480/spdifout";
		spdifout_a_mute = "/pinctrl@ff634480/spdifout_a_mute";
		pdmin = "/pinctrl@ff634480/pdmin";
		dvb_s_ts1_pins = "/pinctrl@ff634480/dvb_s_ts1_pins";
		audio_data = "/audio_data";
		dwc3 = "/dwc3@ff500000";
		usb2_phy_v2 = "/usb2phy@ffe09000";
		usb3_phy_v2 = "/usb3phy@ffe09080";
		dwc2_a = "/dwc2_a@ff400000";
		wdt = "/watchdog@0xffd0f0d0";
		saradc = "/saradc";
		p_tsensor = "/p_tsensor@ff634594";
		d_tsensor = "/d_tsensor@ff800228";
		bl40 = "/bl40";
		cbus = "/soc/cbus@ffd00000";
		gpio_intc = "/soc/cbus@ffd00000/interrupt-controller@f080";
		pwm_ab = "/soc/cbus@ffd00000/pwm@1b000";
		pwm_cd = "/soc/cbus@ffd00000/pwm@1a000";
		pwm_ef = "/soc/cbus@ffd00000/pwm@19000";
		i2c0 = "/soc/cbus@ffd00000/i2c@1f000";
		i2c1 = "/soc/cbus@ffd00000/i2c@1e000";
		i2c2 = "/soc/cbus@ffd00000/i2c@1d000";
		i2c3 = "/soc/cbus@ffd00000/i2c@1c000";
		ad82584f_62 = "/soc/cbus@ffd00000/i2c@1c000/ad82584f_62@62";
		tas5707_36 = "/soc/cbus@ffd00000/i2c@1c000/tas5707_36@36";
		spicc0 = "/soc/cbus@ffd00000/spi@13000";
		spicc1 = "/soc/cbus@ffd00000/spi@15000";
		aobus = "/soc/aobus@ff800000";
		aoclkc = "/soc/aobus@ff800000/clock-controller@0";
		pwm_AO_ab = "/soc/aobus@ff800000/pwm@7000";
		pwm_AO_cd = "/soc/aobus@ff800000/pwm@2000";
		i2c_AO = "/soc/aobus@ff800000/i2c@5000";
		i2c_AO_slave = "/soc/aobus@ff800000/i2c_slave@6000";
		uart_AO = "/soc/aobus@ff800000/serial@3000";
		uart_AO_B = "/soc/aobus@ff800000/serial@4000";
		irblaster = "/soc/aobus@ff800000/meson-irblaster@14c";
		periphs = "/soc/periphs@ff634400";
		hiubus = "/soc/hiubus@ff63c000";
		clkc = "/soc/hiubus@ff63c000/clock-controller@0";
		audiobus = "/soc/audiobus@0xff642000";
		clkaudio = "/soc/audiobus@0xff642000/audio_clocks";
		aml_tdma = "/soc/audiobus@0xff642000/tdma";
		aml_tdmb = "/soc/audiobus@0xff642000/tdmb";
		aml_tdmc = "/soc/audiobus@0xff642000/tdmc";
		tdmlb = "/soc/audiobus@0xff642000/tdm@3";
		aml_i2s2hdmi = "/soc/audiobus@0xff642000/i2s2hdmi";
		aml_spdif = "/soc/audiobus@0xff642000/spdif";
		aml_spdif_b = "/soc/audiobus@0xff642000/spdif_b";
		aml_pdm = "/soc/audiobus@0xff642000/pdm";
		loopback = "/soc/audiobus@0xff642000/loopback@0";
		audioresample = "/soc/audiobus@0xff642000/resample";
		aml_pwrdet = "/soc/audiobus@0xff642000/pwrdet";
		remote = "/rc@0xff808040";
		uart_A = "/serial@ffd24000";
		uart_B = "/serial@ffd23000";
		uart_C = "/serial@ffd22000";
		pcie_A = "/pcieA@fc000000";
		amhdmitx = "/amhdmitx";
		vend_data = "/amhdmitx/vend_data";
		amprime_sl = "/amprime_sl";
		aocec = "/aocec";
		vdin0 = "/vdin0";
		vdin1 = "/vdin1";
		vout_sys = "/vout_sys";
		dummy_venc = "/dummy_venc";
		canvas = "/canvas";
		codec_io = "/codec_io";
		meson_fb = "/meson-fb";
		sd_emmc_c = "/emmc@ffe07000";
		sd_emmc_b1 = "/sd1@ffe05000";
		sd_emmc_b2 = "/sd2@ffe05000";
		sd_emmc_b3 = "/sd3@ffe05000";
		sd_emmc_a = "/sdio@ffe03000";
		nand = "/nfc@0";
		bootloader = "/nfc@0/bootloader";
		nandnormal = "/nfc@0/nandnormal";
		nand_partitions = "/nfc@0/nand_partition";
		meson_cooldev = "/meson-cooldev@0";
		cpufreq_cool0 = "/meson-cooldev@0/cpufreq_cool0";
		cpucore_cool0 = "/meson-cooldev@0/cpucore_cool0";
		gpufreq_cool0 = "/meson-cooldev@0/gpufreq_cool0";
		gpucore_cool0 = "/meson-cooldev@0/gpucore_cool0";
		soc_thermal = "/thermal-zones/soc_thermal";
		pswitch_on = "/thermal-zones/soc_thermal/trips/trip-point@0";
		pcontrol = "/thermal-zones/soc_thermal/trips/trip-point@1";
		phot = "/thermal-zones/soc_thermal/trips/trip-point@2";
		pcritical = "/thermal-zones/soc_thermal/trips/trip-point@3";
		ddr_thermal = "/thermal-zones/ddr_thermal";
		dswitch_on = "/thermal-zones/ddr_thermal/trips/trip-point@0";
		dcontrol = "/thermal-zones/ddr_thermal/trips/trip-point@1";
		dhot = "/thermal-zones/ddr_thermal/trips/trip-point@2";
		dcritical = "/thermal-zones/ddr_thermal/trips/trip-point@3";
		vddcpu0 = "/pwmao_d-regulator";
		defendkey = "/defendkey";
		efuse = "/efuse";
		partitions = "/partitions";
		logo = "/partitions/logo";
		recovery = "/partitions/recovery";
		tee = "/partitions/tee";
		factory = "/partitions/factory";
		misc = "/partitions/misc";
		conf = "/partitions/conf";
		dtbo = "/partitions/dtbo";
		cri_data = "/partitions/cri_data";
		oem = "/partitions/oem";
		metadata = "/partitions/metadata";
		vbmeta = "/partitions/vbmeta";
		param = "/partitions/param";
		boot = "/partitions/boot";
		super = "/partitions/super";
		cache = "/partitions/cache";
		userdata = "/partitions/userdata";
		secmon_reserved = "/reserved-memory/linux,secmon";
		secos_reserved = "/reserved-memory/linux,secos";
		logo_reserved = "/reserved-memory/linux,meson-fb";
		ion_cma_reserved = "/reserved-memory/linux,ion-dev";
		ion_fb_reserved = "/reserved-memory/linux,ion-fb";
		di_cma_reserved = "/reserved-memory/linux,di_cma";
		ppmgr_reserved = "/reserved-memory/linux,ppmgr";
		codec_mm_cma = "/reserved-memory/linux,codec_mm_cma";
		codec_mm_reserved = "/reserved-memory/linux,codec_mm_reserved";
		vdin1_cma_reserved = "/reserved-memory/linux,vdin1_cma";
		amlogic_battery = "/dummy-battery";
		amlogic_charger = "/dummy-charger";
		wifi_pwm_conf = "/wifi_pwm_conf";
		picdec_cma_reserved = "/linux,picdec";
		keysn_0 = "/unifykey/key_0";
		keysn_1 = "/unifykey/key_1";
		keysn_2 = "/unifykey/key_2";
		keysn_3 = "/unifykey/key_3";
		keysn_4 = "/unifykey/key_4";
		keysn_5 = "/unifykey/key_5";
		keysn_6 = "/unifykey/key_6";
		keysn_7 = "/unifykey/key_7";
		keysn_8 = "/unifykey/key_8";
		keysn_9 = "/unifykey/key_9";
		keysn_10 = "/unifykey/key_10";
		keysn_11 = "/unifykey/key_11";
		keysn_12 = "/unifykey/key_12";
		keysn_13 = "/unifykey/key_13";
		keysn_14 = "/unifykey/key_14";
		keysn_15 = "/unifykey/key_15";
		keysn_16 = "/unifykey/key_16";
		keysn_17 = "/unifykey/key_17";
		keysn_18 = "/unifykey/key_18";
		keysn_19 = "/unifykey/key_19";
		keysn_20 = "/unifykey/key_20";
		keysn_21 = "/unifykey/key_21";
		keysn_22 = "/unifykey/key_22";
		keysn_23 = "/unifykey/key_23";
		keysn_24 = "/unifykey/key_24";
		efusekey = "/efusekey";
		key_0 = "/efusekey/key_0";
		key_1 = "/efusekey/key_1";
		key_2 = "/efusekey/key_2";
		key_3 = "/efusekey/key_3";
		dummy_codec = "/dummy";
		pdm_codec = "/dummy";
		amlogic_codec = "/t9015";
		audio_effect = "/eqdrc";
		tdmacpu = "/auge_sound/aml-audio-card,dai-link@0/cpu";
		tdmacodec = "/auge_sound/aml-audio-card,dai-link@0/codec";
		tdmbcodec = "/auge_sound/aml-audio-card,dai-link@1/codec";
		audiolocker = "/locker";
		cpu_opp_table0 = "/cpu_opp_table0";
	};
};
